[part 5 of 6: packages /DBC_SysDesc_C_CANFD/Pkg_Cluster to /DBC_SysDesc_C_CANFD/Pkg_Signal]
AUTOSAR XML (schema 4-2-2)
package /DBC_SysDesc_C_CANFD/Pkg_Cluster
  can cluster C_CANFD: baudrate=500000, protocol-name=CAN, can-fd-baudrate=200000
    can physical channel C_CANFD_Channel: comm-connectors=[Conn_C_CANFD_MVCU]
      frame IBC_0x186: id 0x186, to MVCU, frame-length=32, can-addressing-mode=STANDARD, can-fd-frame-support=true, can-frame-rx-behavior=CAN-FD
        carries pdu IBC_0x186: packing-byte-order=little-endian, start-position=0, update-indication-bit-position=-1
        pdu IBC_0x186: length=32, transmission-mode-false-timing=cyclic-timing={time-offset=0.0, time-period=0.01}, transmission-mode-true-timing=cyclic-timing={time-offset=0.0, time-period=0.01}
          transmission-mode-conditions:
            {data-filter={data-filter-type=ALWAYS, max=255, min=0, offset=0}, i-signal-in-i-pdu=IBC_CRC_186}
            {data-filter={data-filter-type=ALWAYS, max=15, min=0, offset=0}, i-signal-in-i-pdu=IBC_RollingCounter_186}
            {data-filter={data-filter-type=ALWAYS, max=1, min=0, offset=0}, i-signal-in-i-pdu=IBC_WheelPressureReliabilityFL}
            {data-filter={data-filter-type=ALWAYS, max=1, min=0, offset=0}, i-signal-in-i-pdu=IBC_WheelPressureReliabilityFR}
            {data-filter={data-filter-type=ALWAYS, max=1, min=0, offset=0}, i-signal-in-i-pdu=IBC_WheelPressureReliabilityRL}
            {data-filter={data-filter-type=ALWAYS, max=1, min=0, offset=0}, i-signal-in-i-pdu=IBC_WheelPressureReliabilityRR}
            {data-filter={data-filter-type=ALWAYS, max=256, min=0, offset=0}, i-signal-in-i-pdu=IBC_WheelCylinderPressure_FL}
            {data-filter={data-filter-type=ALWAYS, max=256, min=0, offset=0}, i-signal-in-i-pdu=IBC_WheelCylinderPressure_FR}
            {data-filter={data-filter-type=ALWAYS, max=256, min=0, offset=0}, i-signal-in-i-pdu=IBC_WheelCylinderPressure_RL}
            {data-filter={data-filter-type=ALWAYS, max=256, min=0, offset=0}, i-signal-in-i-pdu=IBC_WheelCylinderPressure_RR}
            {data-filter={data-filter-type=ALWAYS, max=1, min=0, offset=0}, i-signal-in-i-pdu=IBC_WheelSlipFLVD}
            {data-filter={data-filter-type=ALWAYS, max=1, min=0, offset=0}, i-signal-in-i-pdu=IBC_WheelSlipFRVD}
            {data-filter={data-filter-type=ALWAYS, max=1, min=0, offset=0}, i-signal-in-i-pdu=IBC_WheelSlipRLVD}
            {data-filter={data-filter-type=ALWAYS, max=1, min=0, offset=0}, i-signal-in-i-pdu=IBC_WheelSlipRRVD}
            {data-filter={data-filter-type=ALWAYS, max=254, min=0}, i-signal-in-i-pdu=IBC_WheelSlipFL}
            {data-filter={data-filter-type=ALWAYS, max=254, min=0}, i-signal-in-i-pdu=IBC_WheelSlipFR}
            {data-filter={data-filter-type=ALWAYS, max=254, min=0}, i-signal-in-i-pdu=IBC_WheelSlipRL}
            {data-filter={data-filter-type=ALWAYS, max=254, min=0}, i-signal-in-i-pdu=IBC_WheelSlipRR}
            {data-filter={data-filter-type=ALWAYS, max=100, min=0, offset=0}, i-signal-in-i-pdu=IBC_Slop_Pencent}
          signal IBC_CRC_186: start 0, 8 bit, little-endian, init-value=0, base-type=uint8, implementation-data-type=DT_IBC_CRC_186, update-indication-bit-position=-1, to MVCU
          signal IBC_RollingCounter_186: start 8, 4 bit, little-endian, init-value=0, base-type=uint8, implementation-data-type=DT_IBC_RollingCounter_186, update-indication-bit-position=-1, to MVCU
          signal IBC_WheelPressureReliabilityFL: start 68, 1 bit, little-endian, init-value=0, base-type=uint8, implementation-data-type=DT_IBC_WheelPressureReliabilityFL, update-indication-bit-position=-1, to MVCU
          signal IBC_WheelPressureReliabilityFR: start 69, 1 bit, little-endian, init-value=0, base-type=uint8, implementation-data-type=DT_IBC_WheelPressureReliabilityFR, update-indication-bit-position=-1, to MVCU
          signal IBC_WheelPressureReliabilityRL: start 70, 1 bit, little-endian, init-value=0, base-type=uint8, implementation-data-type=DT_IBC_WheelPressureReliabilityRL, update-indication-bit-position=-1, to MVCU
          signal IBC_WheelPressureReliabilityRR: start 71, 1 bit, little-endian, init-value=0, base-type=uint8, implementation-data-type=DT_IBC_WheelPressureReliabilityRR, update-indication-bit-position=-1, to MVCU
          signal IBC_WheelCylinderPressure_FL: start 192, 11 bit, little-endian, init-value=0, base-type=uint8, implementation-data-type=DT_IBC_WheelCylinderPressure_FL, update-indication-bit-position=-1, to MVCU
          signal IBC_WheelCylinderPressure_FR: start 208, 11 bit, little-endian, init-value=0, base-type=uint8, implementation-data-type=DT_IBC_WheelCylinderPressure_FR, update-indication-bit-position=-1, to MVCU
          signal IBC_WheelCylinderPressure_RL: start 224, 11 bit, little-endian, init-value=0, base-type=uint8, implementation-data-type=DT_IBC_WheelCylinderPressure_RL, update-indication-bit-position=-1, to MVCU
          signal IBC_WheelCylinderPressure_RR: start 240, 11 bit, little-endian, init-value=0, base-type=uint8, implementation-data-type=DT_IBC_WheelCylinderPressure_RR, update-indication-bit-position=-1, to MVCU
          signal IBC_WheelSlipFLVD: start 76, 1 bit, little-endian, init-value=0, base-type=uint8, implementation-data-type=DT_IBC_WheelSlipFLVD, update-indication-bit-position=-1, to MVCU
          signal IBC_WheelSlipFRVD: start 77, 1 bit, little-endian, init-value=0, base-type=uint8, implementation-data-type=DT_IBC_WheelSlipFRVD, update-indication-bit-position=-1, to MVCU
          signal IBC_WheelSlipRLVD: start 78, 1 bit, little-endian, init-value=0, base-type=uint8, implementation-data-type=DT_IBC_WheelSlipRLVD, update-indication-bit-position=-1, to MVCU
          signal IBC_WheelSlipRRVD: start 79, 1 bit, little-endian, init-value=0, base-type=uint8, implementation-data-type=DT_IBC_WheelSlipRRVD, update-indication-bit-position=-1, to MVCU
          signal IBC_WheelSlipFL: start 80, 8 bit, little-endian, init-value=0, base-type=uint8, implementation-data-type=DT_IBC_WheelSlipFL, update-indication-bit-position=-1, to MVCU
          signal IBC_WheelSlipFR: start 88, 8 bit, little-endian, init-value=0, base-type=uint8, implementation-data-type=DT_IBC_WheelSlipFR, update-indication-bit-position=-1, to MVCU
          signal IBC_WheelSlipRL: start 96, 8 bit, little-endian, init-value=0, base-type=uint8, implementation-data-type=DT_IBC_WheelSlipRL, update-indication-bit-position=-1, to MVCU
          signal IBC_WheelSlipRR: start 104, 8 bit, little-endian, init-value=0, base-type=uint8, implementation-data-type=DT_IBC_WheelSlipRR, update-indication-bit-position=-1, to MVCU
          signal IBC_Slop_Pencent: start 136, 8 bit, little-endian, init-value=0, base-type=uint8, implementation-data-type=DT_IBC_Slop_Pencent, update-indication-bit-position=-1, to MVCU
      frame LMC_0xFA: id 0xFA, to MVCU, frame-length=16, can-addressing-mode=STANDARD, can-fd-frame-support=true, can-frame-rx-behavior=CAN-FD
        carries pdu LMC_0xFA: packing-byte-order=little-endian, start-position=0, update-indication-bit-position=-1
        pdu LMC_0xFA: length=32, transmission-mode-false-timing=cyclic-timing={time-offset=0.0, time-period=0.01}, transmission-mode-true-timing=cyclic-timing={time-offset=0.0, time-period=0.01}
          transmission-mode-conditions:
            {data-filter={data-filter-type=ALWAYS, max=255, min=0, offset=0}, i-signal-in-i-pdu=LMC_CRC_FA}
            {data-filter={data-filter-type=ALWAYS, max=15, min=0, offset=0}, i-signal-in-i-pdu=LMC_RollingCounter_FA}
            {data-filter={data-filter-type=NEW-IS-WITHIN, max=800, min=0}, i-signal-in-i-pdu=LMC_EngTorqDec_Main}
            {data-filter={data-filter-type=ALWAYS, max=1, min=0, offset=0}, i-signal-in-i-pdu=LMC_EngTorqDecActive_Main}
            {data-filter={data-filter-type=ALWAYS, max=3, min=0, offset=0}, i-signal-in-i-pdu=LMC_AMM_St}
            {data-filter={data-filter-type=NEW-IS-WITHIN, max=800, min=0}, i-signal-in-i-pdu=LMC_EngTorqInc_Main}
            {data-filter={data-filter-type=ALWAYS, max=1, min=0, offset=0}, i-signal-in-i-pdu=LMC_EngTorqIncActive_Main}
            {data-filter={data-filter-type=NEW-IS-WITHIN, max=800, min=0}, i-signal-in-i-pdu=LMC_EngTorqDec_Sub}
            {data-filter={data-filter-type=ALWAYS, max=1, min=0, offset=0}, i-signal-in-i-pdu=LMC_EngTorqDecActive_Sub}
            {data-filter={data-filter-type=NEW-IS-WITHIN, max=800, min=0}, i-signal-in-i-pdu=LMC_EngTorqInc_Sub}
            {data-filter={data-filter-type=ALWAYS, max=1, min=0, offset=0}, i-signal-in-i-pdu=LMC_EngTorqIncActive_Sub}
            {data-filter={data-filter-type=ALWAYS, max=1, min=0, offset=0}, i-signal-in-i-pdu=LMC_HSPC_ActiveSt}
            {data-filter={data-filter-type=ALWAYS, max=1, min=0, offset=0}, i-signal-in-i-pdu=LMC_FTSC_ActiveSt}
            {data-filter={data-filter-type=ALWAYS, max=1, min=0, offset=0}, i-signal-in-i-pdu=LMC_SDRM_ActiveSt}
            {data-filter={data-filter-type=ALWAYS, max=1, min=0, offset=0}, i-signal-in-i-pdu=LMC_NSPC_ActiveSt}
            {data-filter={data-filter-type=ALWAYS, max=1, min=0, offset=0}, i-signal-in-i-pdu=LMC_EAF_ActiveSt}
            {data-filter={data-filter-type=ALWAYS, max=1, min=0, offset=0}, i-signal-in-i-pdu=LMC_SelfCheckSt}
            {data-filter={data-filter-type=ALWAYS, max=3, min=0, offset=0}, i-signal-in-i-pdu=LMC_WBDC_ActiveSt}
            {data-filter={data-filter-type=ALWAYS, max=3, min=0, offset=0}, i-signal-in-i-pdu=LMC_LSFCActiveSt}
            {data-filter={data-filter-type=ALWAYS, max=800, min=0, offset=0}, i-signal-in-i-pdu=LMC_EngTorqDec_Main_R}
            {data-filter={data-filter-type=ALWAYS, max=1, min=0, offset=0}, i-signal-in-i-pdu=LMC_EngTorqDecActive_Main_R}
            {data-filter={data-filter-type=ALWAYS, max=800, min=0, offset=0}, i-signal-in-i-pdu=LMC_EngTorqInc_Main_R}
            {data-filter={data-filter-type=ALWAYS, max=1, min=0, offset=0}, i-signal-in-i-pdu=LMC_EngTorqIncActive_Main_R}
          signal LMC_CRC_FA: start 0, 8 bit, little-endian, init-value=0, base-type=uint8, implementation-data-type=DT_LMC_CRC_FA, update-indication-bit-position=-1, to MVCU
          signal LMC_RollingCounter_FA: start 8, 4 bit, little-endian, init-value=0, base-type=uint8, implementation-data-type=DT_LMC_RollingCounter_FA, update-indication-bit-position=-1, to MVCU
          signal LMC_EngTorqDec_Main: start 16, 10 bit, little-endian, init-value=0, base-type=uint16, implementation-data-type=DT_LMC_EngTorqDec_Main, update-indication-bit-position=-1, to MVCU
          signal LMC_EngTorqDecActive_Main: start 26, 1 bit, little-endian, init-value=0, base-type=uint8, implementation-data-type=DT_LMC_EngTorqDecActive_Main, update-indication-bit-position=-1, to MVCU
          signal LMC_AMM_St: start 27, 2 bit, little-endian, init-value=0, base-type=uint8, implementation-data-type=DT_LMC_AMM_St, update-indication-bit-position=-1, to MVCU
          signal LMC_EngTorqInc_Main: start 32, 10 bit, little-endian, init-value=0, base-type=uint16, implementation-data-type=DT_LMC_EngTorqInc_Main, update-indication-bit-position=-1, to MVCU
          signal LMC_EngTorqIncActive_Main: start 42, 1 bit, little-endian, init-value=0, base-type=uint8, implementation-data-type=DT_LMC_EngTorqIncActive_Main, update-indication-bit-position=-1, to MVCU
          signal LMC_EngTorqDec_Sub: start 48, 10 bit, little-endian, init-value=0, base-type=uint16, implementation-data-type=DT_LMC_EngTorqDec_Sub, update-indication-bit-position=-1, to MVCU
          signal LMC_EngTorqDecActive_Sub: start 58, 1 bit, little-endian, init-value=0, base-type=uint8, implementation-data-type=DT_LMC_EngTorqDecActive_Sub, update-indication-bit-position=-1, to MVCU
          signal LMC_EngTorqInc_Sub: start 64, 10 bit, little-endian, init-value=0, base-type=uint16, implementation-data-type=DT_LMC_EngTorqInc_Sub, update-indication-bit-position=-1, to MVCU
          signal LMC_EngTorqIncActive_Sub: start 74, 1 bit, little-endian, init-value=0, base-type=uint8, implementation-data-type=DT_LMC_EngTorqIncActive_Sub, update-indication-bit-position=-1, to MVCU
          signal LMC_SysSt: start 176, 2 bit, little-endian, init-value=0, base-type=uint8, implementation-data-type=DT_LMC_SysSt, update-indication-bit-position=-1, to MVCU
          signal LMC_HSPC_ActiveSt: start 180, 1 bit, little-endian, init-value=0, base-type=uint8, implementation-data-type=DT_LMC_HSPC_ActiveSt, update-indication-bit-position=-1, to MVCU
          signal LMC_FTSC_ActiveSt: start 181, 1 bit, little-endian, init-value=0, base-type=uint8, implementation-data-type=DT_LMC_FTSC_ActiveSt, update-indication-bit-position=-1, to MVCU
          signal LMC_SDRM_ActiveSt: start 182, 1 bit, little-endian, init-value=0, base-type=uint8, implementation-data-type=DT_LMC_SDRM_ActiveSt, update-indication-bit-position=-1, to MVCU
          signal LMC_NSPC_ActiveSt: start 183, 1 bit, little-endian, init-value=0, base-type=uint8, implementation-data-type=DT_LMC_NSPC_ActiveSt, update-indication-bit-position=-1, to MVCU
          signal LMC_EAF_ActiveSt: start 184, 1 bit, little-endian, init-value=0, base-type=uint8, implementation-data-type=DT_LMC_EAF_ActiveSt, update-indication-bit-position=-1, to MVCU
          signal LMC_SelfCheckSt: start 185, 1 bit, little-endian, init-value=0, base-type=uint8, implementation-data-type=DT_LMC_SelfCheckSt, update-indication-bit-position=-1, to MVCU
          signal LMC_WBDC_ActiveSt: start 186, 2 bit, little-endian, init-value=0, base-type=uint8, implementation-data-type=DT_LMC_WBDC_ActiveSt, update-indication-bit-position=-1, to MVCU
          signal LMC_LSFCActiveSt: start 230, 2 bit, little-endian, init-value=0, base-type=uint8, implementation-data-type=DT_LMC_LSFCActiveSt, update-indication-bit-position=-1, to MVCU
          signal LMC_EngTorqDec_Main_R: start 232, 10 bit, little-endian, init-value=0, base-type=uint16, update-indication-bit-position=-1, to MVCU
          signal LMC_EngTorqDecActive_Main_R: start 242, 1 bit, little-endian, init-value=0, base-type=uint8, update-indication-bit-position=-1, to MVCU
          signal LMC_EngTorqInc_Main_R: start 244, 10 bit, little-endian, init-value=0, base-type=uint16, update-indication-bit-position=-1, to MVCU
          signal LMC_EngTorqIncActive_Main_R: start 254, 1 bit, little-endian, init-value=0, base-type=uint8, update-indication-bit-position=-1, to MVCU
      frame LMC_0x18C: id 0x18C, to MVCU, frame-length=32, can-addressing-mode=STANDARD, can-fd-frame-support=true, can-frame-rx-behavior=CAN-FD
        carries pdu LMC_0x18C: packing-byte-order=little-endian, start-position=0, update-indication-bit-position=-1
        pdu LMC_0x18C: length=32, transmission-mode-false-timing=cyclic-timing={time-offset=0.0, time-period=0.02}, transmission-mode-true-timing=cyclic-timing={time-offset=0.0, time-period=0.02}
          transmission-mode-conditions:
            {data-filter={data-filter-type=ALWAYS, max=255, min=0, offset=0}, i-signal-in-i-pdu=LMC_CRC_18C}
            {data-filter={data-filter-type=ALWAYS, max=15, min=0, offset=0}, i-signal-in-i-pdu=LMC_RollingCounter_18C}
            {data-filter={data-filter-type=ALWAYS, max=32767, min=0, offset=0}, i-signal-in-i-pdu=LMC_TqTotalBrakeTorque}
            {data-filter={data-filter-type=ALWAYS, max=1, min=0, offset=0}, i-signal-in-i-pdu=LMC_TqTotalBrakeTorque_Valid}
            {data-filter={data-filter-type=ALWAYS, max=7, min=0, offset=0}, i-signal-in-i-pdu=LMC_CmpUTurnLockwhists}
          signal LMC_CRC_18C: start 0, 8 bit, little-endian, init-value=0, base-type=uint8, implementation-data-type=DT_LMC_CRC_18C, update-indication-bit-position=-1, to MVCU
          signal LMC_RollingCounter_18C: start 8, 4 bit, little-endian, init-value=0, base-type=uint8, implementation-data-type=DT_LMC_RollingCounter_18C, update-indication-bit-position=-1, to MVCU
          signal LMC_TqTotalBrakeTorque: start 80, 15 bit, little-endian, init-value=0, base-type=uint16, implementation-data-type=DT_LMC_TqTotalBrakeTorque, update-indication-bit-position=-1, to MVCU
          signal LMC_TqTotalBrakeTorque_Valid: start 95, 1 bit, little-endian, init-value=0, base-type=uint8, implementation-data-type=DT_LMC_TqTotalBrakeTorque_Valid, update-indication-bit-position=-1, to MVCU
          signal LMC_CmpUTurnLockwhists: start 132, 3 bit, little-endian, init-value=0, base-type=uint8, implementation-data-type=DT_LMC_CmpUTurnLockwhists, update-indication-bit-position=-1, to MVCU
      frame ADDC_0x83: id 0x83, to MVCU, frame-length=32, can-addressing-mode=STANDARD, can-fd-frame-support=true, can-frame-rx-behavior=CAN-FD
        carries pdu ADDC_0x83: packing-byte-order=little-endian, start-position=0, update-indication-bit-position=-1
        pdu ADDC_0x83: length=32, transmission-mode-false-timing=cyclic-timing={time-offset=0.0, time-period=0.02}, transmission-mode-true-timing=cyclic-timing={time-offset=0.0, time-period=0.02}
          transmission-mode-conditions:
            {data-filter={data-filter-type=ALWAYS, max=255, min=0, offset=0}, i-signal-in-i-pdu=ADDC_CRC_83}
            {data-filter={data-filter-type=ALWAYS, max=1, min=0, offset=0}, i-signal-in-i-pdu=ADDC_ACC_AVHReq}
            {data-filter={data-filter-type=ALWAYS, max=1, min=0, offset=0}, i-signal-in-i-pdu=ADDC_ACC_HoldSts}
            {data-filter={data-filter-type=ALWAYS, max=16383, min=0, offset=0}, i-signal-in-i-pdu=ADDC_ACCTargetTrq}
            {data-filter={data-filter-type=ALWAYS, max=1, min=0, offset=0}, i-signal-in-i-pdu=ADDC_ACCTargetTrqVD}
            {data-filter={data-filter-type=ALWAYS, max=1, min=0, offset=0}, i-signal-in-i-pdu=ADDC_ACCTargetTrqBrkVD}
            {data-filter={data-filter-type=ALWAYS, max=8191, min=0, offset=0}, i-signal-in-i-pdu=ADDC_ACCTargetTrqBrk}
            {data-filter={data-filter-type=ALWAYS, max=7, min=0, offset=0}, i-signal-in-i-pdu=ADDC_MAIWarnTrqCtrlFlg}
            {data-filter={data-filter-type=ALWAYS, max=15, min=0, offset=0}, i-signal-in-i-pdu=ADDC_RollingCounter_83}
            {data-filter={data-filter-type=ALWAYS, max=3, min=0, offset=0}, i-signal-in-i-pdu=ADDC_ACC_FunType}
            {data-filter={data-filter-type=ALWAYS, max=7, min=0, offset=0}, i-signal-in-i-pdu=ADDC_ACCMode}
            {data-filter={data-filter-type=ALWAYS, max=1, min=0, offset=0}, i-signal-in-i-pdu=ADDC_Driveoff_Request}
            {data-filter={data-filter-type=ALWAYS, max=1, min=0, offset=0}, i-signal-in-i-pdu=ADDC_DecToStop}
            {data-filter={data-filter-type=ALWAYS, max=1, min=0, offset=0}, i-signal-in-i-pdu=ADDC_ACCAvailable}
            {data-filter={data-filter-type=ALWAYS, max=255, min=0}, i-signal-in-i-pdu=ADDC_ACCTargetAcc}
            {data-filter={data-filter-type=ALWAYS, max=1, min=0, offset=0}, i-signal-in-i-pdu=ADDC_ACCTargetAccVD}
            {data-filter={data-filter-type=ALWAYS, max=3, min=0, offset=0}, i-signal-in-i-pdu=ADDC_ACC_RecordingPulse}
            {data-filter={data-filter-type=ALWAYS, max=1, min=0, offset=0}, i-signal-in-i-pdu=ADDC_VehicleSpeedCtlVD}
            {data-filter={data-filter-type=NEW-IS-WITHIN, max=1800, min=0, offset=0}, i-signal-in-i-pdu=ADDC_VehicleSpeedCtl}
            {data-filter={data-filter-type=ALWAYS, max=3, min=0, offset=0}, i-signal-in-i-pdu=ADDC_ACC_EPBReq}
            {data-filter={data-filter-type=ALWAYS, max=3, min=0, offset=0}, i-signal-in-i-pdu=ADDC_ACC_VehicleDirectCtl}
            {data-filter={data-filter-type=ALWAYS, max=1, min=0, offset=0}, i-signal-in-i-pdu=ADDC_ACC_VehicleDirectCtlVD}
            {data-filter={data-filter-type=NEW-IS-WITHIN, max=64000, min=0}, i-signal-in-i-pdu=ADDC_AEBTargetDec}
            {data-filter={data-filter-type=ALWAYS, max=1, min=0, offset=0}, i-signal-in-i-pdu=ADDC_AEBDecCtrl}
            {data-filter={data-filter-type=ALWAYS, max=7, min=0, offset=0}, i-signal-in-i-pdu=ADDC_AEBMode}
            {data-filter={data-filter-type=ALWAYS, max=1, min=0, offset=0}, i-signal-in-i-pdu=ADDC_AEBAvailable}
            {data-filter={data-filter-type=ALWAYS, max=1, min=0, offset=0}, i-signal-in-i-pdu=ADDC_ACC_VLCCtlReq}
            {data-filter={data-filter-type=ALWAYS, max=1, min=0, offset=0}, i-signal-in-i-pdu=ADDC_ACC_OvrdSts}
            {data-filter={data-filter-type=ALWAYS, max=1, min=0, offset=0}, i-signal-in-i-pdu=ADDC_RCTB_DecReq}
            {data-filter={data-filter-type=ALWAYS, max=1, min=0, offset=0}, i-signal-in-i-pdu=ADDC_RAEB_DecReq}
            {data-filter={data-filter-type=ALWAYS, max=1, min=0, offset=0}, i-signal-in-i-pdu=ADDC_MEB_DecReq}
          signal ADDC_CRC_83: start 0, 8 bit, little-endian, init-value=0, base-type=uint8, implementation-data-type=DT_ADDC_CRC_83, update-indication-bit-position=-1, to MVCU
          signal ADDC_ACC_AVHReq: start 62, 1 bit, little-endian, init-value=0, base-type=uint8, implementation-data-type=DT_ADDC_ACC_AVHReq, update-indication-bit-position=-1, to MVCU
          signal ADDC_ACC_HoldSts: start 61, 1 bit, little-endian, init-value=0, base-type=uint8, implementation-data-type=DT_ADDC_ACC_HoldSts, update-indication-bit-position=-1, to MVCU
          signal ADDC_ACCTargetTrq: start 242, 14 bit, little-endian, init-value=0, base-type=uint16, implementation-data-type=DT_ADDC_ACCTargetTrq, update-indication-bit-position=-1, to MVCU
          signal ADDC_ACCTargetTrqVD: start 241, 1 bit, little-endian, init-value=0, base-type=uint8, implementation-data-type=DT_ADDC_ACCTargetTrqVD, update-indication-bit-position=-1, to MVCU
          signal ADDC_ACCTargetTrqBrkVD: start 240, 1 bit, little-endian, init-value=0, base-type=uint8, implementation-data-type=DT_ADDC_ACCTargetTrqBrkVD, update-indication-bit-position=-1, to MVCU
          signal ADDC_ACCTargetTrqBrk: start 227, 13 bit, little-endian, init-value=0, base-type=uint16, implementation-data-type=DT_ADDC_ACCTargetTrqBrk, update-indication-bit-position=-1, to MVCU
          signal ADDC_MAIWarnTrqCtrlFlg: start 224, 3 bit, little-endian, init-value=0, base-type=uint8, implementation-data-type=DT_ADDC_MAIWarnTrqCtrlFlg, update-indication-bit-position=-1, to MVCU
          signal ADDC_RollingCounter_83: start 8, 4 bit, little-endian, init-value=0, base-type=uint8, implementation-data-type=DT_ADDC_RollingCounter_83, update-indication-bit-position=-1, to MVCU
          signal ADDC_ACC_FunType: start 20, 2 bit, little-endian, init-value=0, base-type=uint8, implementation-data-type=DT_ADDC_ACC_FunType, update-indication-bit-position=-1, to MVCU
          signal ADDC_ACCMode: start 25, 3 bit, little-endian, init-value=0, base-type=uint8, implementation-data-type=DT_ADDC_ACCMode, update-indication-bit-position=-1, to MVCU
          signal ADDC_Driveoff_Request: start 28, 1 bit, little-endian, init-value=0, base-type=uint8, implementation-data-type=DT_ADDC_Driveoff_Request, update-indication-bit-position=-1, to MVCU
          signal ADDC_DecToStop: start 29, 1 bit, little-endian, init-value=0, base-type=uint8, implementation-data-type=DT_ADDC_DecToStop, update-indication-bit-position=-1, to MVCU
          signal ADDC_ACCAvailable: start 30, 1 bit, little-endian, init-value=0, base-type=uint8, implementation-data-type=DT_ADDC_ACCAvailable, update-indication-bit-position=-1, to MVCU
          signal ADDC_ACCTargetAcc: start 32, 8 bit, little-endian, init-value=0, base-type=uint8, implementation-data-type=DT_ADDC_ACCTargetAcc, update-indication-bit-position=-1, to MVCU
          signal ADDC_ACCTargetAccVD: start 40, 1 bit, little-endian, init-value=0, base-type=uint8, implementation-data-type=DT_ADDC_ACCTargetAccVD, update-indication-bit-position=-1, to MVCU
          signal ADDC_ACC_RecordingPulse: start 42, 2 bit, little-endian, init-value=0, base-type=uint8, implementation-data-type=DT_ADDC_ACC_RecordingPulse, update-indication-bit-position=-1, to MVCU
          signal ADDC_VehicleSpeedCtlVD: start 44, 1 bit, little-endian, init-value=0, base-type=uint8, implementation-data-type=DT_ADDC_VehicleSpeedCtlVD, update-indication-bit-position=-1, to MVCU
          signal ADDC_VehicleSpeedCtl: start 45, 11 bit, little-endian, init-value=0, base-type=uint16, implementation-data-type=DT_ADDC_VehicleSpeedCtl, update-indication-bit-position=-1, to MVCU
          signal ADDC_ACC_EPBReq: start 56, 2 bit, little-endian, init-value=0, base-type=uint8, implementation-data-type=DT_ADDC_ACC_EPBReq, update-indication-bit-position=-1, to MVCU
          signal ADDC_ACC_VehicleDirectCtl: start 58, 2 bit, little-endian, init-value=0, base-type=uint8, implementation-data-type=DT_ADDC_ACC_VehicleDirectCtl, update-indication-bit-position=-1, to MVCU
          signal ADDC_ACC_VehicleDirectCtlVD: start 60, 1 bit, little-endian, init-value=0, base-type=uint8, implementation-data-type=DT_ADDC_ACC_VehicleDirectCtlVD, update-indication-bit-position=-1, to MVCU
          signal ADDC_AEBTargetDec: start 64, 16 bit, little-endian, init-value=0, base-type=uint16, implementation-data-type=DT_ADDC_AEBTargetDec, update-indication-bit-position=-1, to MVCU
          signal ADDC_AEBDecCtrl: start 80, 1 bit, little-endian, init-value=0, base-type=uint8, implementation-data-type=DT_ADDC_AEBDecCtrl, update-indication-bit-position=-1, to MVCU
          signal ADDC_AEBMode: start 91, 3 bit, little-endian, init-value=0, base-type=uint8, implementation-data-type=DT_ADDC_AEBMode, update-indication-bit-position=-1, to MVCU
          signal ADDC_AEBAvailable: start 94, 1 bit, little-endian, init-value=0, base-type=uint8, implementation-data-type=DT_ADDC_AEBAvailable, update-indication-bit-position=-1, to MVCU
          signal ADDC_ACC_VLCCtlReq: start 178, 1 bit, little-endian, init-value=0, base-type=uint8, implementation-data-type=DT_ADDC_ACC_VLCCtlReq, update-indication-bit-position=-1, to MVCU
          signal ADDC_ACC_OvrdSts: start 179, 1 bit, little-endian, init-value=0, base-type=uint8, implementation-data-type=DT_ADDC_ACC_OvrdSts, update-indication-bit-position=-1, to MVCU
          signal ADDC_RCTB_DecReq: start 181, 1 bit, little-endian, init-value=0, base-type=uint8, implementation-data-type=DT_ADDC_RCTB_DecReq, update-indication-bit-position=-1, to MVCU
          signal ADDC_RAEB_DecReq: start 193, 1 bit, little-endian, init-value=0, base-type=uint8, implementation-data-type=DT_ADDC_RAEB_DecReq, update-indication-bit-position=-1, to MVCU
          signal ADDC_MEB_DecReq: start 195, 1 bit, little-endian, init-value=0, base-type=uint8, implementation-data-type=DT_ADDC_MEB_DecReq, update-indication-bit-position=-1, to MVCU
      frame ADDC_0x84: id 0x84, to MVCU, frame-length=16, can-addressing-mode=STANDARD, can-fd-frame-support=true, can-frame-rx-behavior=CAN-FD
        carries pdu ADDC_0x84: packing-byte-order=little-endian, start-position=0, update-indication-bit-position=-1
        pdu ADDC_0x84: length=16, transmission-mode-false-timing=cyclic-timing={time-offset=0.0, time-period=0.02}, transmission-mode-true-timing=cyclic-timing={time-offset=0.0, time-period=0.02}
          transmission-mode-conditions:
            {data-filter={data-filter-type=ALWAYS, max=255, min=0, offset=0}, i-signal-in-i-pdu=ADDC_CRC_84}
            {data-filter={data-filter-type=ALWAYS, max=1, min=0, offset=0}, i-signal-in-i-pdu=ADDC_APS_AVHReq}
            {data-filter={data-filter-type=ALWAYS, max=1, min=0, offset=0}, i-signal-in-i-pdu=ADDC_APS_HoldSts}
            {data-filter={data-filter-type=ALWAYS, max=1, min=0, offset=0}, i-signal-in-i-pdu=ADDC_APSTargetTrqBrkVD}
            {data-filter={data-filter-type=ALWAYS, max=8191, min=0, offset=0}, i-signal-in-i-pdu=ADDC_APSTargetTrqBrk}
            {data-filter={data-filter-type=ALWAYS, max=1, min=0, offset=0}, i-signal-in-i-pdu=ADDC_APSTargetTrqVD}
            {data-filter={data-filter-type=ALWAYS, max=16383, min=0, offset=0}, i-signal-in-i-pdu=ADDC_APSTargetTrq}
            {data-filter={data-filter-type=ALWAYS, max=1, min=0, offset=0}, i-signal-in-i-pdu=ADDC_safety_valid}
            {data-filter={data-filter-type=ALWAYS, max=7, min=0, offset=0}, i-signal-in-i-pdu=ADDC_rearsafety_level}
            {data-filter={data-filter-type=ALWAYS, max=7, min=0, offset=0}, i-signal-in-i-pdu=ADDC_frontsafety_level}
            {data-filter={data-filter-type=ALWAYS, max=7, min=0, offset=0}, i-signal-in-i-pdu=ADDC_rightsafety_level}
            {data-filter={data-filter-type=ALWAYS, max=7, min=0, offset=0}, i-signal-in-i-pdu=ADDC_leftsafety_level}
            {data-filter={data-filter-type=ALWAYS, max=15, min=0, offset=0}, i-signal-in-i-pdu=ADDC_RollingCounter_84}
            {data-filter={data-filter-type=ALWAYS, max=1, min=0, offset=0}, i-signal-in-i-pdu=ADDC_APS_EnableReq}
            {data-filter={data-filter-type=ALWAYS, max=1, min=0, offset=0}, i-signal-in-i-pdu=ADDC_APS_WorkSts}
            {data-filter={data-filter-type=ALWAYS, max=1, min=0, offset=0}, i-signal-in-i-pdu=ADDC_APS_PDCVehicleDirectCtlVD}
            {data-filter={data-filter-type=ALWAYS, max=1, min=0, offset=0}, i-signal-in-i-pdu=ADDC_APS_VehicleSpeedCtlVD}
            {data-filter={data-filter-type=ALWAYS, max=3, min=0, offset=0}, i-signal-in-i-pdu=ADDC_APS_PDC_VehicleDirectCtl}
            {data-filter={data-filter-type=NEW-IS-WITHIN, max=65000, min=0}, i-signal-in-i-pdu=ADDC_APS_PDC_SWAngCtl}
            {data-filter={data-filter-type=ALWAYS, max=3, min=0, offset=0}, i-signal-in-i-pdu=ADDC_APS_ParkingReq}
            {data-filter={data-filter-type=ALWAYS, max=1, min=0, offset=0}, i-signal-in-i-pdu=ADDC_APS_EmergenceBrake}
            {data-filter={data-filter-type=ALWAYS, max=1, min=0, offset=0}, i-signal-in-i-pdu=ADDC_APS_TargetAccVD}
            {data-filter={data-filter-type=ALWAYS, max=240, min=0}, i-signal-in-i-pdu=ADDC_APS_TargetAcc}
            {data-filter={data-filter-type=ALWAYS, max=63, min=0, offset=0}, i-signal-in-i-pdu=ADDC_APS_VehicleSpeedCtl}
            {data-filter={data-filter-type=ALWAYS, max=1, min=0, offset=0}, i-signal-in-i-pdu=ADDC_APS_DecToStop}
            {data-filter={data-filter-type=ALWAYS, max=1, min=0, offset=0}, i-signal-in-i-pdu=ADDC_APS_Driveoff_Request}
            {data-filter={data-filter-type=ALWAYS, max=7, min=0, offset=0}, i-signal-in-i-pdu=ADDC_APS_FuncType}
            {data-filter={data-filter-type=ALWAYS, max=1, min=0, offset=0}, i-signal-in-i-pdu=ADDC_APS_Available}
          signal ADDC_CRC_84: start 0, 8 bit, little-endian, init-value=0, base-type=uint8, implementation-data-type=DT_ADDC_CRC_84, update-indication-bit-position=-1, to MVCU
          signal ADDC_APS_AVHReq: start 45, 1 bit, little-endian, init-value=0, base-type=uint8, implementation-data-type=DT_ADDC_APS_AVHReq, update-indication-bit-position=-1, to MVCU
          signal ADDC_APS_HoldSts: start 44, 1 bit, little-endian, init-value=0, base-type=uint8, implementation-data-type=DT_ADDC_APS_HoldSts, update-indication-bit-position=-1, to MVCU
          signal ADDC_APSTargetTrqBrkVD: start 125, 1 bit, little-endian, init-value=0, base-type=uint8, implementation-data-type=DT_ADDC_APSTargetTrqBrkVD, update-indication-bit-position=-1, to MVCU
          signal ADDC_APSTargetTrqBrk: start 112, 13 bit, little-endian, init-value=0, base-type=uint16, implementation-data-type=DT_ADDC_APSTargetTrqBrk, update-indication-bit-position=-1, to MVCU
          signal ADDC_APSTargetTrqVD: start 111, 1 bit, little-endian, init-value=0, base-type=uint8, implementation-data-type=DT_ADDC_APSTargetTrqVD, update-indication-bit-position=-1, to MVCU
          signal ADDC_APSTargetTrq: start 97, 14 bit, little-endian, init-value=0, base-type=uint16, implementation-data-type=DT_ADDC_APSTargetTrq, update-indication-bit-position=-1, to MVCU
          signal ADDC_safety_valid: start 96, 1 bit, little-endian, init-value=0, base-type=uint8, implementation-data-type=DT_ADDC_safety_valid, update-indication-bit-position=-1, to MVCU
          signal ADDC_rearsafety_level: start 93, 3 bit, little-endian, init-value=0, base-type=uint8, implementation-data-type=DT_ADDC_rearsafety_level, update-indication-bit-position=-1, to MVCU
          signal ADDC_frontsafety_level: start 90, 3 bit, little-endian, init-value=0, base-type=uint8, implementation-data-type=DT_ADDC_frontsafety_level, update-indication-bit-position=-1, to MVCU
          signal ADDC_rightsafety_level: start 87, 3 bit, little-endian, init-value=0, base-type=uint8, implementation-data-type=DT_ADDC_rightsafety_level, update-indication-bit-position=-1, to MVCU
          signal ADDC_leftsafety_level: start 84, 3 bit, little-endian, init-value=0, base-type=uint8, implementation-data-type=DT_ADDC_leftsafety_level, update-indication-bit-position=-1, to MVCU
          signal ADDC_RollingCounter_84: start 8, 4 bit, little-endian, init-value=0, base-type=uint8, implementation-data-type=DT_ADDC_RollingCounter_84, update-indication-bit-position=-1, to MVCU
          signal ADDC_APS_EnableReq: start 16, 1 bit, little-endian, init-value=0, base-type=uint8, implementation-data-type=DT_ADDC_APS_EnableReq, update-indication-bit-position=-1, to MVCU
          signal ADDC_APS_WorkSts: start 17, 1 bit, little-endian, init-value=0, base-type=uint8, implementation-data-type=DT_ADDC_APS_WorkSts, update-indication-bit-position=-1, to MVCU
          signal ADDC_APS_PDCVehicleDirectCtlVD: start 19, 1 bit, little-endian, init-value=0, base-type=uint8, implementation-data-type=DT_ADDC_APS_PDCVehicleDirectCtlVD, update-indication-bit-position=-1, to MVCU
          signal ADDC_APS_VehicleSpeedCtlVD: start 20, 1 bit, little-endian, init-value=0, base-type=uint8, implementation-data-type=DT_ADDC_APS_VehicleSpeedCtlVD, update-indication-bit-position=-1, to MVCU
          signal ADDC_APS_PDC_VehicleDirectCtl: start 21, 2 bit, little-endian, init-value=0, base-type=uint8, implementation-data-type=DT_ADDC_APS_PDC_VehicleDirectCtl, update-indication-bit-position=-1, to MVCU
          signal ADDC_APS_PDC_SWAngCtl: start 24, 16 bit, little-endian, init-value=0, base-type=uint16, implementation-data-type=DT_ADDC_APS_PDC_SWAngCtl, update-indication-bit-position=-1, to MVCU
          signal ADDC_APS_ParkingReq: start 40, 2 bit, little-endian, init-value=0, base-type=uint8, implementation-data-type=DT_ADDC_APS_ParkingReq, update-indication-bit-position=-1, to MVCU
          signal ADDC_APS_EmergenceBrake: start 42, 1 bit, little-endian, init-value=0, base-type=uint8, implementation-data-type=DT_ADDC_APS_EmergenceBrake, update-indication-bit-position=-1, to MVCU
          signal ADDC_APS_TargetAccVD: start 43, 1 bit, little-endian, init-value=0, base-type=uint8, implementation-data-type=DT_ADDC_APS_TargetAccVD, update-indication-bit-position=-1, to MVCU
          signal ADDC_APS_TargetAcc: start 56, 8 bit, little-endian, init-value=0, base-type=uint8, implementation-data-type=DT_ADDC_APS_TargetAcc, update-indication-bit-position=-1, to MVCU
          signal ADDC_APS_VehicleSpeedCtl: start 64, 6 bit, little-endian, init-value=0, base-type=uint8, implementation-data-type=DT_ADDC_APS_VehicleSpeedCtl, update-indication-bit-position=-1, to MVCU
          signal ADDC_APS_DecToStop: start 70, 1 bit, little-endian, init-value=0, base-type=uint8, implementation-data-type=DT_ADDC_APS_DecToStop, update-indication-bit-position=-1, to MVCU
          signal ADDC_APS_Driveoff_Request: start 72, 1 bit, little-endian, init-value=0, base-type=uint8, implementation-data-type=DT_ADDC_APS_Driveoff_Request, update-indication-bit-position=-1, to MVCU
          signal ADDC_APS_FuncType: start 73, 3 bit, little-endian, init-value=0, base-type=uint8, implementation-data-type=DT_ADDC_APS_FuncType, update-indication-bit-position=-1, to MVCU
          signal ADDC_APS_Available: start 76, 1 bit, little-endian, init-value=0, base-type=uint8, implementation-data-type=DT_ADDC_APS_Available, update-indication-bit-position=-1, to MVCU
      frame IBC_0xB1: id 0xB1, to MVCU, frame-length=16, can-addressing-mode=STANDARD, can-fd-frame-support=true, can-frame-rx-behavior=CAN-FD
        carries pdu IBC_0xB1: packing-byte-order=little-endian, start-position=0, update-indication-bit-position=-1
        pdu IBC_0xB1: length=16, transmission-mode-false-timing=cyclic-timing={time-offset=0.0, time-period=0.01}, transmission-mode-true-timing=cyclic-timing={time-offset=0.0, time-period=0.01}
          transmission-mode-conditions:
            {data-filter={data-filter-type=ALWAYS, max=255, min=0, offset=0}, i-signal-in-i-pdu=IBC_CRC_B1}
            {data-filter={data-filter-type=ALWAYS, max=15, min=0, offset=0}, i-signal-in-i-pdu=IBC_RollingCounter_B1}
            {data-filter={data-filter-type=NEW-IS-WITHIN, max=800, min=0}, i-signal-in-i-pdu=IBC_EngTorqDec_Main}
            {data-filter={data-filter-type=ALWAYS, max=1, min=0, offset=0}, i-signal-in-i-pdu=IBC_EngTorqDecActive_Main}
            {data-filter={data-filter-type=NEW-IS-WITHIN, max=800, min=0}, i-signal-in-i-pdu=IBC_EngTorqInc_Main}
            {data-filter={data-filter-type=ALWAYS, max=1, min=0, offset=0}, i-signal-in-i-pdu=IBC_EngTorqIncActive_Main}
            {data-filter={data-filter-type=NEW-IS-WITHIN, max=800, min=0}, i-signal-in-i-pdu=IBC_EngTorqDec_Sub}
            {data-filter={data-filter-type=ALWAYS, max=1, min=0, offset=0}, i-signal-in-i-pdu=IBC_EngTorqDecActive_Sub}
            {data-filter={data-filter-type=NEW-IS-WITHIN, max=800, min=0}, i-signal-in-i-pdu=IBC_EngTorqInc_Sub}
            {data-filter={data-filter-type=ALWAYS, max=1, min=0, offset=0}, i-signal-in-i-pdu=IBC_EngTorqIncActive_Sub}
            {data-filter={data-filter-type=ALWAYS, max=800, min=0, offset=0}, i-signal-in-i-pdu=IBC_EngTorqDec_MainR}
            {data-filter={data-filter-type=ALWAYS, max=800, min=0, offset=0}, i-signal-in-i-pdu=IBC_EngTorqDecActive_MainR}
            {data-filter={data-filter-type=ALWAYS, max=800, min=0, offset=0}, i-signal-in-i-pdu=IBC_EngTorqInc_MainR}
            {data-filter={data-filter-type=ALWAYS, max=800, min=0, offset=0}, i-signal-in-i-pdu=IBC_EngTorqIncActive_MainR}
          signal IBC_CRC_B1: start 0, 8 bit, little-endian, init-value=0, base-type=uint8, implementation-data-type=DT_IBC_CRC_B1, update-indication-bit-position=-1, to MVCU
          signal IBC_RollingCounter_B1: start 8, 4 bit, little-endian, init-value=0, base-type=uint8, implementation-data-type=DT_IBC_RollingCounter_B1, update-indication-bit-position=-1, to MVCU
          signal IBC_EngTorqDec_Main: start 16, 10 bit, little-endian, init-value=0, base-type=uint16, implementation-data-type=DT_IBC_EngTorqDec_Main, update-indication-bit-position=-1, to MVCU
          signal IBC_EngTorqDecActive_Main: start 26, 1 bit, little-endian, init-value=0, base-type=uint8, implementation-data-type=DT_IBC_EngTorqDecActive_Main, update-indication-bit-position=-1, to MVCU
          signal IBC_EngTorqInc_Main: start 32, 10 bit, little-endian, init-value=0, base-type=uint16, implementation-data-type=DT_IBC_EngTorqInc_Main, update-indication-bit-position=-1, to MVCU
          signal IBC_EngTorqIncActive_Main: start 42, 1 bit, little-endian, init-value=0, base-type=uint8, implementation-data-type=DT_IBC_EngTorqIncActive_Main, update-indication-bit-position=-1, to MVCU
          signal IBC_EngTorqDec_Sub: start 48, 10 bit, little-endian, init-value=0, base-type=uint16, implementation-data-type=DT_IBC_EngTorqDec_Sub, update-indication-bit-position=-1, to MVCU
          signal IBC_EngTorqDecActive_Sub: start 58, 1 bit, little-endian, init-value=0, base-type=uint8, implementation-data-type=DT_IBC_EngTorqDecActive_Sub, update-indication-bit-position=-1, to MVCU
          signal IBC_EngTorqInc_Sub: start 64, 10 bit, little-endian, init-value=0, base-type=uint16, implementation-data-type=DT_IBC_EngTorqInc_Sub, update-indication-bit-position=-1, to MVCU
          signal IBC_EngTorqIncActive_Sub: start 74, 1 bit, little-endian, init-value=0, base-type=uint8, implementation-data-type=DT_IBC_EngTorqIncActive_Sub, update-indication-bit-position=-1, to MVCU
          signal IBC_EngTorqDec_MainR: start 80, 10 bit, little-endian, init-value=0, base-type=uint8, implementation-data-type=DT_IBC_EngTorqDec_MainR, update-indication-bit-position=-1, to MVCU
          signal IBC_EngTorqDecActive_MainR: start 90, 1 bit, little-endian, init-value=0, base-type=uint8, implementation-data-type=DT_IBC_EngTorqDecActive_MainR, update-indication-bit-position=-1, to MVCU
          signal IBC_EngTorqInc_MainR: start 96, 10 bit, little-endian, init-value=0, base-type=uint8, implementation-data-type=DT_IBC_EngTorqInc_MainR, update-indication-bit-position=-1, to MVCU
          signal IBC_EngTorqIncActive_MainR: start 106, 1 bit, little-endian, init-value=0, base-type=uint8, implementation-data-type=DT_IBC_EngTorqIncActive_MainR, update-indication-bit-position=-1, to MVCU
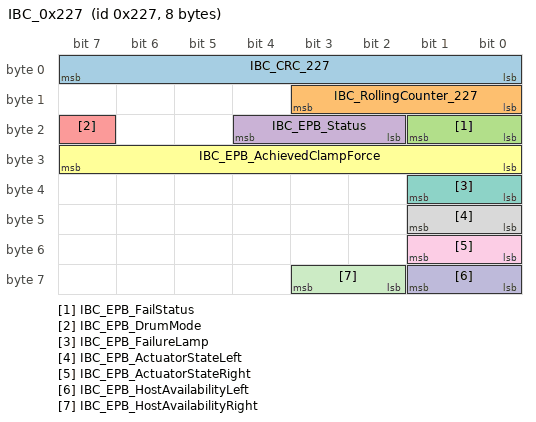
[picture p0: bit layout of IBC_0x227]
      frame IBC_0x227: id 0x227, to MVCU, frame-length=8, can-addressing-mode=STANDARD, can-fd-frame-support=true, can-frame-rx-behavior=CAN-FD
        carries pdu IBC_0x227: packing-byte-order=little-endian, start-position=0, update-indication-bit-position=-1
        pdu IBC_0x227: length=8, transmission-mode-false-timing=cyclic-timing={time-offset=0.0, time-period=0.02}, transmission-mode-true-timing=cyclic-timing={time-offset=0.0, time-period=0.02}
          transmission-mode-conditions:
            {data-filter={data-filter-type=ALWAYS, max=255, min=0, offset=0}, i-signal-in-i-pdu=IBC_CRC_227}
            {data-filter={data-filter-type=ALWAYS, max=15, min=0, offset=0}, i-signal-in-i-pdu=IBC_RollingCounter_227}
            {data-filter={data-filter-type=ALWAYS, max=3, min=0, offset=0}, i-signal-in-i-pdu=IBC_EPB_FailStatus}
            {data-filter={data-filter-type=ALWAYS, max=7, min=0, offset=0}, i-signal-in-i-pdu=IBC_EPB_Status}
            {data-filter={data-filter-type=ALWAYS, max=1, min=0, offset=0}, i-signal-in-i-pdu=IBC_EPB_DrumMode}
            {data-filter={data-filter-type=ALWAYS, max=255, min=0, offset=0}, i-signal-in-i-pdu=IBC_EPB_AchievedClampForce}
            {data-filter={data-filter-type=ALWAYS, max=3, min=0, offset=0}, i-signal-in-i-pdu=IBC_EPB_FailureLamp}
            {data-filter={data-filter-type=ALWAYS, max=3, min=0, offset=0}, i-signal-in-i-pdu=IBC_EPB_ActuatorStateLeft}
            {data-filter={data-filter-type=ALWAYS, max=3, min=0, offset=0}, i-signal-in-i-pdu=IBC_EPB_ActuatorStateRight}
            {data-filter={data-filter-type=ALWAYS, max=3, min=0, offset=0}, i-signal-in-i-pdu=IBC_EPB_HostAvailabilityLeft}
            {data-filter={data-filter-type=ALWAYS, max=3, min=0, offset=0}, i-signal-in-i-pdu=IBC_EPB_HostAvailabilityRight}
          signal IBC_CRC_227: start 0, 8 bit, little-endian, init-value=0, base-type=uint8, implementation-data-type=DT_IBC_CRC_227, update-indication-bit-position=-1, to MVCU
          signal IBC_RollingCounter_227: start 8, 4 bit, little-endian, init-value=0, base-type=uint8, implementation-data-type=DT_IBC_RollingCounter_227, update-indication-bit-position=-1, to MVCU
          signal IBC_EPB_FailStatus: start 16, 2 bit, little-endian, init-value=0, base-type=uint8, implementation-data-type=DT_IBC_EPB_FailStatus, update-indication-bit-position=-1, to MVCU
          signal IBC_EPB_Status: start 18, 3 bit, little-endian, init-value=0, base-type=uint8, implementation-data-type=DT_IBC_EPB_Status, update-indication-bit-position=-1, to MVCU
          signal IBC_EPB_DrumMode: start 23, 1 bit, little-endian, init-value=0, base-type=uint8, implementation-data-type=DT_IBC_EPB_DrumMode, update-indication-bit-position=-1, to MVCU
          signal IBC_EPB_AchievedClampForce: start 24, 8 bit, little-endian, init-value=0, base-type=uint8, implementation-data-type=DT_IBC_EPB_AchievedClampForce, update-indication-bit-position=-1, to MVCU
          signal IBC_EPB_FailureLamp: start 32, 2 bit, little-endian, init-value=0, base-type=uint8, implementation-data-type=DT_IBC_EPB_FailureLamp, update-indication-bit-position=-1, to MVCU
          signal IBC_EPB_ActuatorStateLeft: start 40, 2 bit, little-endian, init-value=0, base-type=uint8, implementation-data-type=DT_IBC_EPB_ActuatorStateLeft, update-indication-bit-position=-1, to MVCU
          signal IBC_EPB_ActuatorStateRight: start 48, 2 bit, little-endian, init-value=0, base-type=uint8, implementation-data-type=DT_IBC_EPB_ActuatorStateRight, update-indication-bit-position=-1, to MVCU
          signal IBC_EPB_HostAvailabilityLeft: start 56, 2 bit, little-endian, init-value=0, base-type=uint8, implementation-data-type=DT_IBC_EPB_HostAvailabilityLeft, update-indication-bit-position=-1, to MVCU
          signal IBC_EPB_HostAvailabilityRight: start 58, 2 bit, little-endian, init-value=0, base-type=uint8, implementation-data-type=DT_IBC_EPB_HostAvailabilityRight, update-indication-bit-position=-1, to MVCU
      frame EPS_0x18D: id 0x18D, to MVCU, frame-length=32, can-addressing-mode=STANDARD, can-fd-frame-support=true, can-frame-rx-behavior=CAN-FD
        carries pdu EPS_0x18D: packing-byte-order=little-endian, start-position=0, update-indication-bit-position=-1
        pdu EPS_0x18D: length=32, transmission-mode-false-timing=cyclic-timing={time-offset=0.0, time-period=0.01}, transmission-mode-true-timing=cyclic-timing={time-offset=0.0, time-period=0.01}
          transmission-mode-conditions:
            {data-filter={data-filter-type=ALWAYS, max=255, min=0, offset=0}, i-signal-in-i-pdu=EPS_CRC_18D}
            {data-filter={data-filter-type=ALWAYS, max=15, min=0, offset=0}, i-signal-in-i-pdu=EPS_RollingCounter_18D}
            {data-filter={data-filter-type=ALWAYS, max=1, min=0, offset=0}, i-signal-in-i-pdu=EPS_Fault}
            {data-filter={data-filter-type=ALWAYS, max=1, min=0, offset=0}, i-signal-in-i-pdu=EPS_CalibrationSts}
            {data-filter={data-filter-type=ALWAYS, max=1, min=0, offset=0}, i-signal-in-i-pdu=EPS_FailureSts}
            {data-filter={data-filter-type=ALWAYS, max=1, min=0, offset=0}, i-signal-in-i-pdu=EPS_SteeringAngleValidData}
            {data-filter={data-filter-type=ALWAYS, max=1, min=0, offset=0}, i-signal-in-i-pdu=EPS_SteeringAngleSpeedValidData}
            {data-filter={data-filter-type=NEW-IS-WITHIN, max=65000, min=0}, i-signal-in-i-pdu=EPS_SteerWheelAngle}
            {data-filter={data-filter-type=ALWAYS, max=254, min=0, offset=0}, i-signal-in-i-pdu=EPS_SteerWheelRotSpd}
            {data-filter={data-filter-type=ALWAYS, max=1, min=0, offset=0}, i-signal-in-i-pdu=EPS_SelfCheckSt}
            {data-filter={data-filter-type=ALWAYS, max=2, min=0, offset=0}, i-signal-in-i-pdu=EPS_AssistanceSts}
          signal EPS_CRC_18D: start 0, 8 bit, little-endian, init-value=0, base-type=uint8, implementation-data-type=DT_EPS_CRC_18D, update-indication-bit-position=-1, to MVCU
          signal EPS_RollingCounter_18D: start 8, 4 bit, little-endian, init-value=0, base-type=uint8, implementation-data-type=DT_EPS_RollingCounter_18D, update-indication-bit-position=-1, to MVCU
          signal EPS_Fault: start 16, 1 bit, little-endian, init-value=0, base-type=uint8, implementation-data-type=DT_EPS_Fault, update-indication-bit-position=-1, to MVCU
          signal EPS_CalibrationSts: start 17, 1 bit, little-endian, init-value=0, base-type=uint8, implementation-data-type=DT_EPS_CalibrationSts, update-indication-bit-position=-1, to MVCU
          signal EPS_FailureSts: start 18, 1 bit, little-endian, init-value=0, base-type=uint8, implementation-data-type=DT_EPS_FailureSts, update-indication-bit-position=-1, to MVCU
          signal EPS_SteeringAngleValidData: start 19, 1 bit, little-endian, init-value=0, base-type=uint8, implementation-data-type=DT_EPS_SteeringAngleValidData, update-indication-bit-position=-1, to MVCU
          signal EPS_SteeringAngleSpeedValidData: start 20, 1 bit, little-endian, init-value=0, base-type=uint8, implementation-data-type=DT_EPS_SteeringAngleSpeedValidData, update-indication-bit-position=-1, to MVCU
          signal EPS_SteerWheelAngle: start 24, 16 bit, little-endian, init-value=0, base-type=uint16, implementation-data-type=DT_EPS_SteerWheelAngle, update-indication-bit-position=-1, to MVCU
          signal EPS_SteerWheelRotSpd: start 40, 8 bit, little-endian, init-value=0, base-type=uint8, implementation-data-type=DT_EPS_SteerWheelRotSpd, update-indication-bit-position=-1, to MVCU
          signal EPS_SelfCheckSt: start 62, 1 bit, little-endian, init-value=0, base-type=uint8, implementation-data-type=DT_EPS_SelfCheckSt, update-indication-bit-position=-1, to MVCU
          signal EPS_AssistanceSts: start 69, 2 bit, little-endian, init-value=0, base-type=uint8, implementation-data-type=DT_EPS_AssistanceSts, update-indication-bit-position=-1, to MVCU
      frame IBC_0x182: id 0x182, to MVCU, frame-length=8, can-addressing-mode=STANDARD, can-fd-frame-support=true, can-frame-rx-behavior=CAN-FD
        carries pdu IBC_0x182: packing-byte-order=little-endian, start-position=0, update-indication-bit-position=-1
        pdu IBC_0x182: length=8, transmission-mode-false-timing=cyclic-timing={time-offset=0.0, time-period=0.02}, transmission-mode-true-timing=cyclic-timing={time-offset=0.0, time-period=0.02}
          transmission-mode-conditions:
            {data-filter={data-filter-type=ALWAYS, max=255, min=0, offset=0}, i-signal-in-i-pdu=IBC_CRC_182}
            {data-filter={data-filter-type=ALWAYS, max=15, min=0, offset=0}, i-signal-in-i-pdu=IBC_RollingCounter_182}
            {data-filter={data-filter-type=NEW-IS-WITHIN, max=45000, min=0, offset=0}, i-signal-in-i-pdu=IBC_VehicleSpeed}
            {data-filter={data-filter-type=ALWAYS, max=1, min=0, offset=0}, i-signal-in-i-pdu=IBC_VehicleSpeedVD}
            {data-filter={data-filter-type=ALWAYS, max=1, min=0, offset=0}, i-signal-in-i-pdu=IBC_ABSActive}
            {data-filter={data-filter-type=ALWAYS, max=1, min=0, offset=0}, i-signal-in-i-pdu=IBC_ABSFailed}
            {data-filter={data-filter-type=ALWAYS, max=1, min=0, offset=0}, i-signal-in-i-pdu=IBC_TCSActive}
            {data-filter={data-filter-type=ALWAYS, max=1, min=0, offset=0}, i-signal-in-i-pdu=IBC_TCSFailed}
            {data-filter={data-filter-type=ALWAYS, max=1, min=0, offset=0}, i-signal-in-i-pdu=IBC_ESCFunctionStatus}
            {data-filter={data-filter-type=ALWAYS, max=1, min=0, offset=0}, i-signal-in-i-pdu=IBC_BrakeForce}
            {data-filter={data-filter-type=ALWAYS, max=1, min=0, offset=0}, i-signal-in-i-pdu=IBC_Vehiclestandstill}
            {data-filter={data-filter-type=ALWAYS, max=1, min=0, offset=0}, i-signal-in-i-pdu=IBC_EBDFailed}
            {data-filter={data-filter-type=ALWAYS, max=1, min=0, offset=0}, i-signal-in-i-pdu=IBC_EBDActive}
            {data-filter={data-filter-type=ALWAYS, max=1, min=0, offset=0}, i-signal-in-i-pdu=IBC_VDCActive}
            {data-filter={data-filter-type=ALWAYS, max=1, min=0, offset=0}, i-signal-in-i-pdu=IBC_VDCFailed}
            {data-filter={data-filter-type=ALWAYS, max=1, min=0, offset=0}, i-signal-in-i-pdu=IBC_EDCActive}
            {data-filter={data-filter-type=ALWAYS, max=1, min=0, offset=0}, i-signal-in-i-pdu=IBC_EDCFailed}
            {data-filter={data-filter-type=ALWAYS, max=1, min=0, offset=0}, i-signal-in-i-pdu=IBC_SystemInitializeStatus}
            {data-filter={data-filter-type=ALWAYS, max=1, min=0, offset=0}, i-signal-in-i-pdu=IBC_BTCSActive}
            {data-filter={data-filter-type=ALWAYS, max=1, min=0, offset=0}, i-signal-in-i-pdu=IBC_ETCSActive}
            {data-filter={data-filter-type=ALWAYS, max=1, min=0, offset=0}, i-signal-in-i-pdu=IBC_ARPActive}
            {data-filter={data-filter-type=ALWAYS, max=1, min=0, offset=0}, i-signal-in-i-pdu=IBC_VCU_DrumMode}
            {data-filter={data-filter-type=ALWAYS, max=1, min=0, offset=0}, i-signal-in-i-pdu=IBC_EscapeModeSts}
            {data-filter={data-filter-type=ALWAYS, max=1, min=0, offset=0}, i-signal-in-i-pdu=IBC_TSAActive}
            {data-filter={data-filter-type=ALWAYS, max=3, min=0, offset=0}, i-signal-in-i-pdu=IBC_TSAStatus}
          signal IBC_CRC_182: start 0, 8 bit, little-endian, init-value=0, base-type=uint8, implementation-data-type=DT_IBC_CRC_182, update-indication-bit-position=-1, to MVCU
          signal IBC_RollingCounter_182: start 8, 4 bit, little-endian, init-value=0, base-type=uint8, implementation-data-type=DT_IBC_RollingCounter_182, update-indication-bit-position=-1, to MVCU
          signal IBC_VehicleSpeed: start 16, 16 bit, little-endian, init-value=0, base-type=uint16, implementation-data-type=DT_IBC_VehicleSpeed, update-indication-bit-position=-1, to MVCU
          signal IBC_VehicleSpeedVD: start 32, 1 bit, little-endian, init-value=0, base-type=uint8, implementation-data-type=DT_IBC_VehicleSpeedVD, update-indication-bit-position=-1, to MVCU
          signal IBC_ABSActive: start 33, 1 bit, little-endian, init-value=0, base-type=uint8, implementation-data-type=DT_IBC_ABSActive, update-indication-bit-position=-1, to MVCU
          signal IBC_ABSFailed: start 34, 1 bit, little-endian, init-value=0, base-type=uint8, implementation-data-type=DT_IBC_ABSFailed, update-indication-bit-position=-1, to MVCU
          signal IBC_TCSActive: start 35, 1 bit, little-endian, init-value=0, base-type=uint8, implementation-data-type=DT_IBC_TCSActive, update-indication-bit-position=-1, to MVCU
          signal IBC_TCSFailed: start 36, 1 bit, little-endian, init-value=0, base-type=uint8, implementation-data-type=DT_IBC_TCSFailed, update-indication-bit-position=-1, to MVCU
          signal IBC_ESCFunctionStatus: start 37, 1 bit, little-endian, init-value=0, base-type=uint8, implementation-data-type=DT_IBC_ESCFunctionStatus, update-indication-bit-position=-1, to MVCU
          signal IBC_BrakeForce: start 38, 1 bit, little-endian, init-value=0, base-type=uint8, implementation-data-type=DT_IBC_BrakeForce, update-indication-bit-position=-1, to MVCU
          signal IBC_Vehiclestandstill: start 39, 1 bit, little-endian, init-value=0, base-type=uint8, implementation-data-type=DT_IBC_Vehiclestandstill, update-indication-bit-position=-1, to MVCU
          signal IBC_EBDFailed: start 40, 1 bit, little-endian, init-value=0, base-type=uint8, implementation-data-type=DT_IBC_EBDFailed, update-indication-bit-position=-1, to MVCU
          signal IBC_EBDActive: start 41, 1 bit, little-endian, init-value=0, base-type=uint8, implementation-data-type=DT_IBC_EBDActive, update-indication-bit-position=-1, to MVCU
          signal IBC_VDCActive: start 42, 1 bit, little-endian, init-value=0, base-type=uint8, implementation-data-type=DT_IBC_VDCActive, update-indication-bit-position=-1, to MVCU
          signal IBC_VDCFailed: start 43, 1 bit, little-endian, init-value=0, base-type=uint8, implementation-data-type=DT_IBC_VDCFailed, update-indication-bit-position=-1, to MVCU
          signal IBC_EDCActive: start 44, 1 bit, little-endian, init-value=0, base-type=uint8, implementation-data-type=DT_IBC_EDCActive, update-indication-bit-position=-1, to MVCU
          signal IBC_EDCFailed: start 45, 1 bit, little-endian, init-value=0, base-type=uint8, implementation-data-type=DT_IBC_EDCFailed, update-indication-bit-position=-1, to MVCU
          signal IBC_SystemInitializeStatus: start 46, 1 bit, little-endian, init-value=0, base-type=uint8, implementation-data-type=DT_IBC_SystemInitializeStatus, update-indication-bit-position=-1, to MVCU
          signal IBC_BTCSActive: start 47, 1 bit, little-endian, init-value=0, base-type=uint8, implementation-data-type=DT_IBC_BTCSActive, update-indication-bit-position=-1, to MVCU
          signal IBC_ETCSActive: start 48, 1 bit, little-endian, init-value=0, base-type=uint8, implementation-data-type=DT_IBC_ETCSActive, update-indication-bit-position=-1, to MVCU
          signal IBC_ARPActive: start 49, 1 bit, little-endian, init-value=0, base-type=uint8, implementation-data-type=DT_IBC_ARPActive, update-indication-bit-position=-1, to MVCU
          signal IBC_VCU_DrumMode: start 50, 1 bit, little-endian, init-value=0, base-type=uint8, implementation-data-type=DT_IBC_VCU_DrumMode, update-indication-bit-position=-1, to MVCU
          signal IBC_EscapeModeSts: start 52, 1 bit, little-endian, init-value=0, base-type=uint8, implementation-data-type=DT_IBC_EscapeModeSts, update-indication-bit-position=-1, to MVCU
          signal IBC_TSAActive: start 53, 1 bit, little-endian, init-value=0, base-type=uint8, implementation-data-type=DT_IBC_TSAActive, update-indication-bit-position=-1, to MVCU
          signal IBC_TSAStatus: start 54, 3 bit, little-endian, init-value=0, base-type=uint8, implementation-data-type=DT_IBC_TSAStatus, update-indication-bit-position=-1, to MVCU
      frame IBC_0x183: id 0x183, to MVCU, frame-length=16, can-addressing-mode=STANDARD, can-fd-frame-support=true, can-frame-rx-behavior=CAN-FD
        carries pdu IBC_0x183: packing-byte-order=little-endian, start-position=0, update-indication-bit-position=-1
        pdu IBC_0x183: length=16, transmission-mode-false-timing=cyclic-timing={time-offset=0.0, time-period=0.02}, transmission-mode-true-timing=cyclic-timing={time-offset=0.0, time-period=0.02}
          transmission-mode-conditions:
            {data-filter={data-filter-type=ALWAYS, max=255, min=0, offset=0}, i-signal-in-i-pdu=IBC_CRC_183}
            {data-filter={data-filter-type=ALWAYS, max=15, min=0, offset=0}, i-signal-in-i-pdu=IBC_RollingCounter_183}
            {data-filter={data-filter-type=NEW-IS-WITHIN, max=32767, min=0, offset=0}, i-signal-in-i-pdu=IBC_RecuBrakeTorqueRequest}
            {data-filter={data-filter-type=ALWAYS, max=3, min=0, offset=0}, i-signal-in-i-pdu=IBC_RecuBrakeTorqueRequest_Q}
            {data-filter={data-filter-type=ALWAYS, max=2, min=0, offset=0}, i-signal-in-i-pdu=IBC_sOutputRodDriverPer_Q}
            {data-filter={data-filter-type=ALWAYS, max=3, min=0, offset=0}, i-signal-in-i-pdu=IBC_BrakePedalApplied_Q}
            {data-filter={data-filter-type=ALWAYS, max=2, min=0, offset=0}, i-signal-in-i-pdu=IBC_HydraTorqTgtAct_Q}
            {data-filter={data-filter-type=NEW-IS-WITHIN, max=32767, min=0, offset=0}, i-signal-in-i-pdu=IBC_HydraTorqTgtAct}
            {data-filter={data-filter-type=ALWAYS, max=1, min=0, offset=0}, i-signal-in-i-pdu=IBC_BrakePedalApplied}
            {data-filter={data-filter-type=ALWAYS, max=100, min=0, offset=0}, i-signal-in-i-pdu=IBC_sOutputRodDriverPer}
            {data-filter={data-filter-type=ALWAYS, max=1, min=0, offset=0}, i-signal-in-i-pdu=IBC_HydraTorqAvailable}
            {data-filter={data-filter-type=ALWAYS, max=7, min=0, offset=0}, i-signal-in-i-pdu=IBC_CtrlMode}
            {data-filter={data-filter-type=ALWAYS, max=1, min=0, offset=0}, i-signal-in-i-pdu=IBC_QDC_HydraTorqTgt}
            {data-filter={data-filter-type=NEW-IS-WITHIN, max=4063, min=0}, i-signal-in-i-pdu=IBC_InPutRodDriver}
            {data-filter={data-filter-type=ALWAYS, max=3, min=0, offset=0}, i-signal-in-i-pdu=IBC_InPutRodDriver_Q}
            {data-filter={data-filter-type=ALWAYS, max=7, min=0, offset=0}, i-signal-in-i-pdu=IBC_SystemAssistedStatus}
            {data-filter={data-filter-type=ALWAYS, max=1, min=0, offset=0}, i-signal-in-i-pdu=IBC_EngTorq_VLC_Vaild}
            {data-filter={data-filter-type=NEW-IS-WITHIN, max=16000, min=0}, i-signal-in-i-pdu=IBC_EngTorq_VLC}
            {data-filter={data-filter-type=NEW-IS-WITHIN, max=32767, min=0}, i-signal-in-i-pdu=IBC_BrkTorq_VLC}
            {data-filter={data-filter-type=ALWAYS, max=1, min=0, offset=0}, i-signal-in-i-pdu=IBC_BrkTorq_VLC_Vaild}
          signal IBC_CRC_183: start 0, 8 bit, little-endian, init-value=0, base-type=uint8, implementation-data-type=DT_IBC_CRC_183, update-indication-bit-position=-1, to MVCU
          signal IBC_RollingCounter_183: start 8, 4 bit, little-endian, init-value=0, base-type=uint8, implementation-data-type=DT_IBC_RollingCounter_183, update-indication-bit-position=-1, to MVCU
          signal IBC_RecuBrakeTorqueRequest: start 16, 15 bit, little-endian, init-value=0, base-type=uint16, implementation-data-type=DT_IBC_RecuBrakeTorqueRequest, update-indication-bit-position=-1, to MVCU
          signal IBC_RecuBrakeTorqueRequest_Q: start 32, 2 bit, little-endian, init-value=0, base-type=uint8, implementation-data-type=DT_IBC_RecuBrakeTorqueRequest_Q, update-indication-bit-position=-1, to MVCU
          signal IBC_sOutputRodDriverPer_Q: start 34, 2 bit, little-endian, init-value=0, base-type=uint8, implementation-data-type=DT_IBC_sOutputRodDriverPer_Q, update-indication-bit-position=-1, to MVCU
          signal IBC_BrakePedalApplied_Q: start 36, 2 bit, little-endian, init-value=0, base-type=uint8, implementation-data-type=DT_IBC_BrakePedalApplied_Q, update-indication-bit-position=-1, to MVCU
          signal IBC_HydraTorqTgtAct_Q: start 38, 2 bit, little-endian, init-value=0, base-type=uint8, implementation-data-type=DT_IBC_HydraTorqTgtAct_Q, update-indication-bit-position=-1, to MVCU
          signal IBC_HydraTorqTgtAct: start 40, 15 bit, little-endian, init-value=0, base-type=uint16, implementation-data-type=DT_IBC_HydraTorqTgtAct, update-indication-bit-position=-1, to MVCU
          signal IBC_BrakePedalApplied: start 55, 1 bit, little-endian, init-value=0, base-type=uint8, implementation-data-type=DT_IBC_BrakePedalApplied, update-indication-bit-position=-1, to MVCU
          signal IBC_sOutputRodDriverPer: start 56, 7 bit, little-endian, init-value=0, base-type=uint8, implementation-data-type=DT_IBC_sOutputRodDriverPer, update-indication-bit-position=-1, to MVCU
          signal IBC_HydraTorqAvailable: start 63, 1 bit, little-endian, init-value=0, base-type=uint8, implementation-data-type=DT_IBC_HydraTorqAvailable, update-indication-bit-position=-1, to MVCU
          signal IBC_CtrlMode: start 64, 3 bit, little-endian, init-value=0, base-type=uint8, implementation-data-type=DT_IBC_CtrlMode, update-indication-bit-position=-1, to MVCU
          signal IBC_QDC_HydraTorqTgt: start 67, 1 bit, little-endian, init-value=0, base-type=uint8, implementation-data-type=DT_IBC_QDC_HydraTorqTgt, update-indication-bit-position=-1, to MVCU
          signal IBC_InPutRodDriver: start 68, 12 bit, little-endian, init-value=0, base-type=uint16, implementation-data-type=DT_IBC_InPutRodDriver, update-indication-bit-position=-1, to MVCU
          signal IBC_InPutRodDriver_Q: start 80, 2 bit, little-endian, init-value=0, base-type=uint8, implementation-data-type=DT_IBC_InPutRodDriver_Q, update-indication-bit-position=-1, to MVCU
          signal IBC_SystemAssistedStatus: start 82, 3 bit, little-endian, init-value=0, base-type=uint8, implementation-data-type=DT_IBC_SystemAssistedStatus, update-indication-bit-position=-1, to MVCU
          signal IBC_EngTorq_VLC_Vaild: start 87, 1 bit, little-endian, init-value=0, base-type=uint8, implementation-data-type=DT_IBC_EngTorq_VLC_Vaild, update-indication-bit-position=-1, to MVCU
          signal IBC_EngTorq_VLC: start 88, 14 bit, little-endian, init-value=0, base-type=uint16, implementation-data-type=DT_IBC_EngTorq_VLC, update-indication-bit-position=-1, to MVCU
          signal IBC_BrkTorq_VLC: start 112, 15 bit, little-endian, init-value=0, base-type=uint16, implementation-data-type=DT_IBC_BrkTorq_VLC, update-indication-bit-position=-1, to MVCU
          signal IBC_BrkTorq_VLC_Vaild: start 127, 1 bit, little-endian, init-value=0, base-type=uint8, implementation-data-type=DT_IBC_BrkTorq_VLC_Vaild, update-indication-bit-position=-1, to MVCU
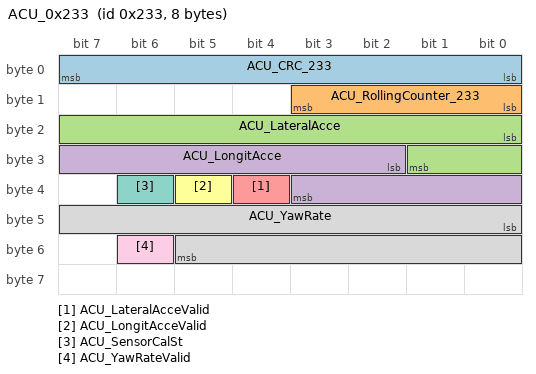
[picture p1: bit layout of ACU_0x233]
      frame ACU_0x233: id 0x233, to MVCU, frame-length=8, can-addressing-mode=STANDARD, can-fd-frame-support=true, can-frame-rx-behavior=CAN-FD
        carries pdu ACU_0x233: packing-byte-order=little-endian, start-position=0, update-indication-bit-position=-1
        pdu ACU_0x233: length=8, transmission-mode-false-timing=cyclic-timing={time-offset=0.0, time-period=0.02}, transmission-mode-true-timing=cyclic-timing={time-offset=0.0, time-period=0.02}
          transmission-mode-conditions:
            {data-filter={data-filter-type=ALWAYS, max=255, min=0, offset=0}, i-signal-in-i-pdu=ACU_CRC_233}
            {data-filter={data-filter-type=ALWAYS, max=15, min=0, offset=0}, i-signal-in-i-pdu=ACU_RollingCounter_233}
            {data-filter={data-filter-type=NEW-IS-WITHIN, max=1021, min=0}, i-signal-in-i-pdu=ACU_LateralAcce}
            {data-filter={data-filter-type=NEW-IS-WITHIN, max=1021, min=0}, i-signal-in-i-pdu=ACU_LongitAcce}
            {data-filter={data-filter-type=ALWAYS, max=1, min=0, offset=0}, i-signal-in-i-pdu=ACU_LateralAcceValid}
            {data-filter={data-filter-type=ALWAYS, max=1, min=0, offset=0}, i-signal-in-i-pdu=ACU_LongitAcceValid}
            {data-filter={data-filter-type=ALWAYS, max=1, min=0, offset=0}, i-signal-in-i-pdu=ACU_SensorCalSt}
            {data-filter={data-filter-type=NEW-IS-WITHIN, max=16382, min=0}, i-signal-in-i-pdu=ACU_YawRate}
            {data-filter={data-filter-type=ALWAYS, max=1, min=0, offset=0}, i-signal-in-i-pdu=ACU_YawRateValid}
          signal ACU_CRC_233: start 0, 8 bit, little-endian, init-value=0, base-type=uint8, implementation-data-type=DT_ACU_CRC_233, update-indication-bit-position=-1, to MVCU
          signal ACU_RollingCounter_233: start 8, 4 bit, little-endian, init-value=0, base-type=uint8, implementation-data-type=DT_ACU_RollingCounter_233, update-indication-bit-position=-1, to MVCU
          signal ACU_LateralAcce: start 16, 10 bit, little-endian, init-value=0, base-type=uint16, implementation-data-type=DT_ACU_LateralAcce, update-indication-bit-position=-1, to MVCU
          signal ACU_LongitAcce: start 26, 10 bit, little-endian, init-value=0, base-type=uint16, implementation-data-type=DT_ACU_LongitAcce, update-indication-bit-position=-1, to MVCU
          signal ACU_LateralAcceValid: start 36, 1 bit, little-endian, init-value=0, base-type=uint8, implementation-data-type=DT_ACU_LateralAcceValid, update-indication-bit-position=-1, to MVCU
          signal ACU_LongitAcceValid: start 37, 1 bit, little-endian, init-value=0, base-type=uint8, implementation-data-type=DT_ACU_LongitAcceValid, update-indication-bit-position=-1, to MVCU
          signal ACU_SensorCalSt: start 38, 1 bit, little-endian, init-value=0, base-type=uint8, implementation-data-type=DT_ACU_SensorCalSt, update-indication-bit-position=-1, to MVCU
          signal ACU_YawRate: start 40, 14 bit, little-endian, init-value=0, base-type=uint16, implementation-data-type=DT_ACU_YawRate, update-indication-bit-position=-1, to MVCU
          signal ACU_YawRateValid: start 54, 1 bit, little-endian, init-value=0, base-type=uint8, implementation-data-type=DT_ACU_YawRateValid, update-indication-bit-position=-1, to MVCU
      frame IBC_0x184: id 0x184, to MVCU, frame-length=32, can-addressing-mode=STANDARD, can-fd-frame-support=true, can-frame-rx-behavior=CAN-FD
        carries pdu IBC_0x184: packing-byte-order=little-endian, start-position=0, update-indication-bit-position=-1
        pdu IBC_0x184: length=32, transmission-mode-false-timing=cyclic-timing={time-offset=0.0, time-period=0.02}, transmission-mode-true-timing=cyclic-timing={time-offset=0.0, time-period=0.02}
          transmission-mode-conditions:
            {data-filter={data-filter-type=ALWAYS, max=255, min=0, offset=0}, i-signal-in-i-pdu=IBC_CRC_184}
            {data-filter={data-filter-type=ALWAYS, max=15, min=0, offset=0}, i-signal-in-i-pdu=IBC_RollingCounter_184}
            {data-filter={data-filter-type=NEW-IS-WITHIN, max=45000, min=0, offset=0}, i-signal-in-i-pdu=IBC_FLWheelSpeedKPH}
            {data-filter={data-filter-type=NEW-IS-WITHIN, max=45000, min=0, offset=0}, i-signal-in-i-pdu=IBC_FRWheelSpeedKPH}
            {data-filter={data-filter-type=NEW-IS-WITHIN, max=45000, min=0, offset=0}, i-signal-in-i-pdu=IBC_RLWheelSpeedKPH}
            {data-filter={data-filter-type=NEW-IS-WITHIN, max=45000, min=0, offset=0}, i-signal-in-i-pdu=IBC_RRWheelSpeedKPH}
            {data-filter={data-filter-type=ALWAYS, max=3, min=0, offset=0}, i-signal-in-i-pdu=IBC_FLWheelDirection}
            {data-filter={data-filter-type=ALWAYS, max=3, min=0, offset=0}, i-signal-in-i-pdu=IBC_FRWheelDirection}
            {data-filter={data-filter-type=ALWAYS, max=3, min=0, offset=0}, i-signal-in-i-pdu=IBC_RLWheelDirection}
            {data-filter={data-filter-type=ALWAYS, max=3, min=0, offset=0}, i-signal-in-i-pdu=IBC_RRWheelDirection}
            {data-filter={data-filter-type=ALWAYS, max=1, min=0, offset=0}, i-signal-in-i-pdu=IBC_FLWheelSpeedVD}
            {data-filter={data-filter-type=ALWAYS, max=1, min=0, offset=0}, i-signal-in-i-pdu=IBC_FRWheelSpeedVD}
            {data-filter={data-filter-type=ALWAYS, max=1, min=0, offset=0}, i-signal-in-i-pdu=IBC_RLWheelSpeedVD}
            {data-filter={data-filter-type=ALWAYS, max=1, min=0, offset=0}, i-signal-in-i-pdu=IBC_RRWheelSpeedVD}
            {data-filter={data-filter-type=NEW-IS-WITHIN, max=4094, min=0, offset=0}, i-signal-in-i-pdu=IBC_FLWheelSpeedRC}
            {data-filter={data-filter-type=NEW-IS-WITHIN, max=4094, min=0, offset=0}, i-signal-in-i-pdu=IBC_FRWheelSpeedRC}
            {data-filter={data-filter-type=NEW-IS-WITHIN, max=4094, min=0, offset=0}, i-signal-in-i-pdu=IBC_RLWheelSpeedRC}
            {data-filter={data-filter-type=NEW-IS-WITHIN, max=4094, min=0, offset=0}, i-signal-in-i-pdu=IBC_RRWheelSpeedRC}
            {data-filter={data-filter-type=ALWAYS, max=7, min=0, offset=0}, i-signal-in-i-pdu=IBC_DiscTemperatureFL}
            {data-filter={data-filter-type=ALWAYS, max=1, min=0, offset=0}, i-signal-in-i-pdu=IBC_DiscTemperatureFLVD}
            {data-filter={data-filter-type=ALWAYS, max=7, min=0, offset=0}, i-signal-in-i-pdu=IBC_DiscTemperatureFR}
            {data-filter={data-filter-type=ALWAYS, max=1, min=0, offset=0}, i-signal-in-i-pdu=IBC_DiscTemperatureFRVD}
            {data-filter={data-filter-type=ALWAYS, max=7, min=0, offset=0}, i-signal-in-i-pdu=IBC_DiscTemperatureRL}
            {data-filter={data-filter-type=ALWAYS, max=1, min=0, offset=0}, i-signal-in-i-pdu=IBC_DiscTemperatureRLVD}
            {data-filter={data-filter-type=ALWAYS, max=7, min=0, offset=0}, i-signal-in-i-pdu=IBC_DiscTemperatureRR}
            {data-filter={data-filter-type=ALWAYS, max=1, min=0, offset=0}, i-signal-in-i-pdu=IBC_DiscTemperatureRRVD}
          signal IBC_CRC_184: start 0, 8 bit, little-endian, init-value=0, base-type=uint8, implementation-data-type=DT_IBC_CRC_184, update-indication-bit-position=-1, to MVCU
          signal IBC_RollingCounter_184: start 8, 4 bit, little-endian, init-value=0, base-type=uint8, implementation-data-type=DT_IBC_RollingCounter_184, update-indication-bit-position=-1, to MVCU
          signal IBC_FLWheelSpeedKPH: start 16, 16 bit, little-endian, init-value=0, base-type=uint16, implementation-data-type=DT_IBC_FLWheelSpeedKPH, update-indication-bit-position=-1, to MVCU
          signal IBC_FRWheelSpeedKPH: start 32, 16 bit, little-endian, init-value=0, base-type=uint16, implementation-data-type=DT_IBC_FRWheelSpeedKPH, update-indication-bit-position=-1, to MVCU
          signal IBC_RLWheelSpeedKPH: start 48, 16 bit, little-endian, init-value=0, base-type=uint16, implementation-data-type=DT_IBC_RLWheelSpeedKPH, update-indication-bit-position=-1, to MVCU
          signal IBC_RRWheelSpeedKPH: start 64, 16 bit, little-endian, init-value=0, base-type=uint16, implementation-data-type=DT_IBC_RRWheelSpeedKPH, update-indication-bit-position=-1, to MVCU
          signal IBC_FLWheelDirection: start 80, 2 bit, little-endian, init-value=0, base-type=uint8, implementation-data-type=DT_IBC_FLWheelDirection, update-indication-bit-position=-1, to MVCU
          signal IBC_FRWheelDirection: start 82, 2 bit, little-endian, init-value=0, base-type=uint8, implementation-data-type=DT_IBC_FRWheelDirection, update-indication-bit-position=-1, to MVCU
          signal IBC_RLWheelDirection: start 84, 2 bit, little-endian, init-value=0, base-type=uint8, implementation-data-type=DT_IBC_RLWheelDirection, update-indication-bit-position=-1, to MVCU
          signal IBC_RRWheelDirection: start 86, 2 bit, little-endian, init-value=0, base-type=uint8, implementation-data-type=DT_IBC_RRWheelDirection, update-indication-bit-position=-1, to MVCU
          signal IBC_FLWheelSpeedVD: start 88, 1 bit, little-endian, init-value=0, base-type=uint8, implementation-data-type=DT_IBC_FLWheelSpeedVD, update-indication-bit-position=-1, to MVCU
          signal IBC_FRWheelSpeedVD: start 89, 1 bit, little-endian, init-value=0, base-type=uint8, implementation-data-type=DT_IBC_FRWheelSpeedVD, update-indication-bit-position=-1, to MVCU
          signal IBC_RLWheelSpeedVD: start 90, 1 bit, little-endian, init-value=0, base-type=uint8, implementation-data-type=DT_IBC_RLWheelSpeedVD, update-indication-bit-position=-1, to MVCU
          signal IBC_RRWheelSpeedVD: start 91, 1 bit, little-endian, init-value=0, base-type=uint8, implementation-data-type=DT_IBC_RRWheelSpeedVD, update-indication-bit-position=-1, to MVCU
          signal IBC_FLWheelSpeedRC: start 92, 12 bit, little-endian, init-value=0, base-type=uint16, implementation-data-type=DT_IBC_FLWheelSpeedRC, update-indication-bit-position=-1, to MVCU
          signal IBC_FRWheelSpeedRC: start 104, 12 bit, little-endian, init-value=0, base-type=uint16, implementation-data-type=DT_IBC_FRWheelSpeedRC, update-indication-bit-position=-1, to MVCU
          signal IBC_RLWheelSpeedRC: start 116, 12 bit, little-endian, init-value=0, base-type=uint16, implementation-data-type=DT_IBC_RLWheelSpeedRC, update-indication-bit-position=-1, to MVCU
          signal IBC_RRWheelSpeedRC: start 128, 12 bit, little-endian, init-value=0, base-type=uint16, implementation-data-type=DT_IBC_RRWheelSpeedRC, update-indication-bit-position=-1, to MVCU
          signal IBC_DiscTemperatureFL: start 184, 3 bit, little-endian, init-value=0, base-type=uint8, implementation-data-type=DT_IBC_DiscTemperatureFL, update-indication-bit-position=-1, to MVCU
          signal IBC_DiscTemperatureFLVD: start 187, 1 bit, little-endian, init-value=0, base-type=uint8, implementation-data-type=DT_IBC_DiscTemperatureFLVD, update-indication-bit-position=-1, to MVCU
          signal IBC_DiscTemperatureFR: start 188, 3 bit, little-endian, init-value=0, base-type=uint8, implementation-data-type=DT_IBC_DiscTemperatureFR, update-indication-bit-position=-1, to MVCU
          signal IBC_DiscTemperatureFRVD: start 191, 1 bit, little-endian, init-value=0, base-type=uint8, implementation-data-type=DT_IBC_DiscTemperatureFRVD, update-indication-bit-position=-1, to MVCU
          signal IBC_DiscTemperatureRL: start 192, 3 bit, little-endian, init-value=0, base-type=uint8, implementation-data-type=DT_IBC_DiscTemperatureRL, update-indication-bit-position=-1, to MVCU
          signal IBC_DiscTemperatureRLVD: start 195, 1 bit, little-endian, init-value=0, base-type=uint8, implementation-data-type=DT_IBC_DiscTemperatureRLVD, update-indication-bit-position=-1, to MVCU
          signal IBC_DiscTemperatureRR: start 196, 3 bit, little-endian, init-value=0, base-type=uint8, implementation-data-type=DT_IBC_DiscTemperatureRR, update-indication-bit-position=-1, to MVCU
          signal IBC_DiscTemperatureRRVD: start 199, 1 bit, little-endian, init-value=0, base-type=uint8, implementation-data-type=DT_IBC_DiscTemperatureRRVD, update-indication-bit-position=-1, to MVCU
      frame FSC_0x142: id 0x142, to MVCU, frame-length=16, can-addressing-mode=STANDARD, can-fd-frame-support=true, can-frame-rx-behavior=CAN-FD
        carries pdu FSC_0x142: packing-byte-order=little-endian, start-position=0, update-indication-bit-position=-1
        pdu FSC_0x142: length=16, transmission-mode-false-timing=cyclic-timing={time-offset=0.0, time-period=0.02}, transmission-mode-true-timing=cyclic-timing={time-offset=0.0, time-period=0.02}
          transmission-mode-conditions:
            {data-filter={data-filter-type=ALWAYS, max=255, min=0, offset=0}, i-signal-in-i-pdu=FSC_CRC_142}
            {data-filter={data-filter-type=ALWAYS, max=15, min=0, offset=0}, i-signal-in-i-pdu=FSC_RollingCounter_142}
            {data-filter={data-filter-type=ALWAYS, max=7, min=0, offset=0}, i-signal-in-i-pdu=FSC_LCC_Mode}
          signal FSC_CRC_142: start 0, 8 bit, little-endian, init-value=0, base-type=uint8, implementation-data-type=DT_FSC_CRC_142, update-indication-bit-position=-1, to MVCU
          signal FSC_RollingCounter_142: start 8, 4 bit, little-endian, init-value=0, base-type=uint8, implementation-data-type=DT_FSC_RollingCounter_142, update-indication-bit-position=-1, to MVCU
          signal FSC_LCC_Mode: start 40, 3 bit, little-endian, init-value=0, base-type=uint8, implementation-data-type=DT_FSC_LCC_Mode, update-indication-bit-position=-1, to MVCU
      frame IBC_0x185: id 0x185, to MVCU, frame-length=16, can-addressing-mode=STANDARD, can-fd-frame-support=true, can-frame-rx-behavior=CAN-FD
        carries pdu IBC_0x185: packing-byte-order=little-endian, start-position=0, update-indication-bit-position=-1
        pdu IBC_0x185: length=16, transmission-mode-false-timing=cyclic-timing={time-offset=0.0, time-period=0.02}, transmission-mode-true-timing=cyclic-timing={time-offset=0.0, time-period=0.02}
          transmission-mode-conditions:
            {data-filter={data-filter-type=ALWAYS, max=255, min=0, offset=0}, i-signal-in-i-pdu=IBC_CRC_185}
            {data-filter={data-filter-type=ALWAYS, max=15, min=0, offset=0}, i-signal-in-i-pdu=IBC_RollingCounter_185}
            {data-filter={data-filter-type=NEW-IS-WITHIN, max=2046, min=0, offset=0}, i-signal-in-i-pdu=IBC_PlungerPressure}
            {data-filter={data-filter-type=ALWAYS, max=1, min=0, offset=0}, i-signal-in-i-pdu=IBC_PlungerPressure_Q}
            {data-filter={data-filter-type=NEW-IS-WITHIN, max=2046, min=0, offset=0}, i-signal-in-i-pdu=IBC_SimulatorPressure}
            {data-filter={data-filter-type=ALWAYS, max=1, min=0, offset=0}, i-signal-in-i-pdu=IBC_SimulatorPressure_Q}
            {data-filter={data-filter-type=ALWAYS, max=3, min=0, offset=0}, i-signal-in-i-pdu=IBC_HMI_WarningOn}
            {data-filter={data-filter-type=ALWAYS, max=1, min=0, offset=0}, i-signal-in-i-pdu=IBC_MIL_WarningOn}
            {data-filter={data-filter-type=NEW-IS-WITHIN, max=1021, min=0}, i-signal-in-i-pdu=IBC_LongitAcceAct}
            {data-filter={data-filter-type=ALWAYS, max=1, min=0, offset=0}, i-signal-in-i-pdu=IBC_LongitAcceActValid}
            {data-filter={data-filter-type=ALWAYS, max=3, min=0, offset=0}, i-signal-in-i-pdu=IBC_brakeFluidWarning}
            {data-filter={data-filter-type=ALWAYS, max=1, min=0, offset=0}, i-signal-in-i-pdu=IBC_SCM_Active}
            {data-filter={data-filter-type=ALWAYS, max=1, min=0, offset=0}, i-signal-in-i-pdu=IBC_SCM_Failed}
            {data-filter={data-filter-type=ALWAYS, max=1, min=0, offset=0}, i-signal-in-i-pdu=IBC_CDPAvailable}
            {data-filter={data-filter-type=ALWAYS, max=1, min=0, offset=0}, i-signal-in-i-pdu=IBC_CDPIntervention}
            {data-filter={data-filter-type=ALWAYS, max=1, min=0, offset=0}, i-signal-in-i-pdu=IBC_AEB_active}
            {data-filter={data-filter-type=ALWAYS, max=1, min=0, offset=0}, i-signal-in-i-pdu=IBC_AEBdecAvailable}
            {data-filter={data-filter-type=ALWAYS, max=3, min=0, offset=0}, i-signal-in-i-pdu=IBC_AVHStatus}
            {data-filter={data-filter-type=ALWAYS, max=1, min=0, offset=0}, i-signal-in-i-pdu=IBC_AVHAvailable}
            {data-filter={data-filter-type=ALWAYS, max=1, min=0, offset=0}, i-signal-in-i-pdu=IBC_HHCActive}
            {data-filter={data-filter-type=ALWAYS, max=1, min=0, offset=0}, i-signal-in-i-pdu=IBC_HHCFailed}
            {data-filter={data-filter-type=ALWAYS, max=1, min=0, offset=0}, i-signal-in-i-pdu=IBC_CDD_Available_APA}
            {data-filter={data-filter-type=ALWAYS, max=1, min=0, offset=0}, i-signal-in-i-pdu=IBC_CDD_Active_APA}
            {data-filter={data-filter-type=ALWAYS, max=1, min=0, offset=0}, i-signal-in-i-pdu=IBC_CDD_Available_ACC}
            {data-filter={data-filter-type=ALWAYS, max=1, min=0, offset=0}, i-signal-in-i-pdu=IBC_CDD_Active_ACC}
            {data-filter={data-filter-type=ALWAYS, max=3, min=0, offset=0}, i-signal-in-i-pdu=IBC_HDCStatus}
            {data-filter={data-filter-type=ALWAYS, max=1, min=0, offset=0}, i-signal-in-i-pdu=IBC_HDCAvailable}
            {data-filter={data-filter-type=ALWAYS, max=3, min=0, offset=0}, i-signal-in-i-pdu=IBC_CSTStatus}
            {data-filter={data-filter-type=ALWAYS, max=1, min=0, offset=0}, i-signal-in-i-pdu=IBC_CSTAvailable}
            {data-filter={data-filter-type=ALWAYS, max=1, min=0, offset=0}, i-signal-in-i-pdu=IBC_VLC_Available_ACC}
            {data-filter={data-filter-type=ALWAYS, max=1, min=0, offset=0}, i-signal-in-i-pdu=IBC_VLC_Active_ACC}
            {data-filter={data-filter-type=ALWAYS, max=1, min=0, offset=0}, i-signal-in-i-pdu=IBC_VLC_Available_APA}
            {data-filter={data-filter-type=ALWAYS, max=1, min=0, offset=0}, i-signal-in-i-pdu=IBC_VLC_Active_APA}
            {data-filter={data-filter-type=ALWAYS, max=3, min=0, offset=0}, i-signal-in-i-pdu=IBC_VehicleHoldStatus}
            {data-filter={data-filter-type=NEW-IS-WITHIN, max=32767, min=0, offset=0}, i-signal-in-i-pdu=IBC_DrvrBrkTqAtWhlsReqd}
          signal IBC_CRC_185: start 0, 8 bit, little-endian, init-value=0, base-type=uint8, implementation-data-type=DT_IBC_CRC_185, update-indication-bit-position=-1, to MVCU
          signal IBC_RollingCounter_185: start 8, 4 bit, little-endian, init-value=0, base-type=uint8, implementation-data-type=DT_IBC_RollingCounter_185, update-indication-bit-position=-1, to MVCU
          signal IBC_PlungerPressure: start 16, 11 bit, little-endian, init-value=0, base-type=uint16, implementation-data-type=DT_IBC_PlungerPressure, update-indication-bit-position=-1, to MVCU
          signal IBC_PlungerPressure_Q: start 27, 1 bit, little-endian, init-value=0, base-type=uint8, implementation-data-type=DT_IBC_PlungerPressure_Q, update-indication-bit-position=-1, to MVCU
          signal IBC_SimulatorPressure: start 28, 11 bit, little-endian, init-value=0, base-type=uint16, implementation-data-type=DT_IBC_SimulatorPressure, update-indication-bit-position=-1, to MVCU
          signal IBC_SimulatorPressure_Q: start 39, 1 bit, little-endian, init-value=0, base-type=uint8, implementation-data-type=DT_IBC_SimulatorPressure_Q, update-indication-bit-position=-1, to MVCU
          signal IBC_HMI_WarningOn: start 45, 2 bit, little-endian, init-value=0, base-type=uint8, implementation-data-type=DT_IBC_HMI_WarningOn, update-indication-bit-position=-1, to MVCU
          signal IBC_MIL_WarningOn: start 47, 1 bit, little-endian, init-value=0, base-type=uint8, implementation-data-type=DT_IBC_MIL_WarningOn, update-indication-bit-position=-1, to MVCU
          signal IBC_LongitAcceAct: start 48, 10 bit, little-endian, init-value=0, base-type=uint16, implementation-data-type=DT_IBC_LongitAcceAct, update-indication-bit-position=-1, to MVCU
          signal IBC_LongitAcceActValid: start 58, 1 bit, little-endian, init-value=0, base-type=uint8, implementation-data-type=DT_IBC_LongitAcceActValid, update-indication-bit-position=-1, to MVCU
          signal IBC_brakeFluidWarning: start 59, 2 bit, little-endian, init-value=0, base-type=uint8, implementation-data-type=DT_IBC_brakeFluidWarning, update-indication-bit-position=-1, to MVCU
          signal IBC_SCM_Active: start 69, 1 bit, little-endian, init-value=0, base-type=uint8, implementation-data-type=DT_IBC_SCM_Active, update-indication-bit-position=-1, to MVCU
          signal IBC_SCM_Failed: start 70, 1 bit, little-endian, init-value=0, base-type=uint8, implementation-data-type=DT_IBC_SCM_Failed, update-indication-bit-position=-1, to MVCU
          signal IBC_CDPAvailable: start 78, 1 bit, little-endian, init-value=0, base-type=uint8, implementation-data-type=DT_IBC_CDPAvailable, update-indication-bit-position=-1, to MVCU
          signal IBC_CDPIntervention: start 79, 1 bit, little-endian, init-value=0, base-type=uint8, implementation-data-type=DT_IBC_CDPIntervention, update-indication-bit-position=-1, to MVCU
          signal IBC_AEB_active: start 80, 1 bit, little-endian, init-value=0, base-type=uint8, implementation-data-type=DT_IBC_AEB_active, update-indication-bit-position=-1, to MVCU
          signal IBC_AEBdecAvailable: start 81, 1 bit, little-endian, init-value=0, base-type=uint8, implementation-data-type=DT_IBC_AEBdecAvailable, update-indication-bit-position=-1, to MVCU
          signal IBC_AVHStatus: start 82, 2 bit, little-endian, init-value=0, base-type=uint8, implementation-data-type=DT_IBC_AVHStatus, update-indication-bit-position=-1, to MVCU
          signal IBC_AVHAvailable: start 84, 1 bit, little-endian, init-value=0, base-type=uint8, implementation-data-type=DT_IBC_AVHAvailable, update-indication-bit-position=-1, to MVCU
          signal IBC_HHCActive: start 85, 1 bit, little-endian, init-value=0, base-type=uint8, implementation-data-type=DT_IBC_HHCActive, update-indication-bit-position=-1, to MVCU
          signal IBC_HHCFailed: start 86, 1 bit, little-endian, init-value=0, base-type=uint8, implementation-data-type=DT_IBC_HHCFailed, update-indication-bit-position=-1, to MVCU
          signal IBC_CDD_Available_APA: start 87, 1 bit, little-endian, init-value=0, base-type=uint8, implementation-data-type=DT_IBC_CDD_Available_APA, update-indication-bit-position=-1, to MVCU
          signal IBC_CDD_Active_APA: start 88, 1 bit, little-endian, init-value=0, base-type=uint8, implementation-data-type=DT_IBC_CDD_Active_APA, update-indication-bit-position=-1, to MVCU
          signal IBC_CDD_Available_ACC: start 90, 1 bit, little-endian, init-value=0, base-type=uint8, implementation-data-type=DT_IBC_CDD_Available_ACC, update-indication-bit-position=-1, to MVCU
          signal IBC_CDD_Active_ACC: start 91, 1 bit, little-endian, init-value=0, base-type=uint8, implementation-data-type=DT_IBC_CDD_Active_ACC, update-indication-bit-position=-1, to MVCU
          signal IBC_HDCStatus: start 94, 2 bit, little-endian, init-value=0, base-type=uint8, implementation-data-type=DT_IBC_HDCStatus, update-indication-bit-position=-1, to MVCU
          signal IBC_HDCAvailable: start 96, 1 bit, little-endian, init-value=0, base-type=uint8, implementation-data-type=DT_IBC_HDCAvailable, update-indication-bit-position=-1, to MVCU
          signal IBC_CSTStatus: start 97, 2 bit, little-endian, init-value=0, base-type=uint8, implementation-data-type=DT_IBC_CSTStatus, update-indication-bit-position=-1, to MVCU
          signal IBC_CSTAvailable: start 99, 1 bit, little-endian, init-value=0, base-type=uint8, implementation-data-type=DT_IBC_CSTAvailable, update-indication-bit-position=-1, to MVCU
          signal IBC_VLC_Available_ACC: start 100, 1 bit, little-endian, init-value=0, base-type=uint8, implementation-data-type=DT_IBC_VLC_Available_ACC, update-indication-bit-position=-1, to MVCU
          signal IBC_VLC_Active_ACC: start 101, 1 bit, little-endian, init-value=0, base-type=uint8, implementation-data-type=DT_IBC_VLC_Active_ACC, update-indication-bit-position=-1, to MVCU
          signal IBC_VLC_Available_APA: start 102, 1 bit, little-endian, init-value=0, base-type=uint8, implementation-data-type=DT_IBC_VLC_Available_APA, update-indication-bit-position=-1, to MVCU
          signal IBC_VLC_Active_APA: start 103, 1 bit, little-endian, init-value=0, base-type=uint8, implementation-data-type=DT_IBC_VLC_Active_APA, update-indication-bit-position=-1, to MVCU
          signal IBC_VehicleHoldStatus: start 104, 2 bit, little-endian, init-value=0, base-type=uint8, implementation-data-type=DT_IBC_VehicleHoldStatus, update-indication-bit-position=-1, to MVCU
          signal IBC_DrvrBrkTqAtWhlsReqd: start 113, 15 bit, little-endian, init-value=0, base-type=uint16, implementation-data-type=DT_IBC_DrvrBrkTqAtWhlsReqd, update-indication-bit-position=-1, to MVCU
      frame ACU_0x2A3: id 0x2A3, to MVCU, frame-length=16, can-addressing-mode=STANDARD, can-fd-frame-support=true, can-frame-rx-behavior=CAN-FD
        carries pdu ACU_0x2A3: packing-byte-order=little-endian, start-position=0, update-indication-bit-position=-1
        pdu ACU_0x2A3: length=16, transmission-mode-false-timing=cyclic-timing={time-offset=0.0, time-period=0.1}, transmission-mode-true-timing=cyclic-timing={time-offset=0.0, time-period=0.1}
          transmission-mode-conditions:
            {data-filter={data-filter-type=ALWAYS, max=255, min=0, offset=0}, i-signal-in-i-pdu=ACU_CRC_2A3}
            {data-filter={data-filter-type=ALWAYS, max=1, min=0, offset=0}, i-signal-in-i-pdu=ACU_Trigger}
            {data-filter={data-filter-type=ALWAYS, max=15, min=0, offset=0}, i-signal-in-i-pdu=ACU_RollingCounter_2A3}
            {data-filter={data-filter-type=ALWAYS, max=1, min=0, offset=0}, i-signal-in-i-pdu=ACU_TotalCrashOutputSts}
            {data-filter={data-filter-type=ALWAYS, max=1, min=0, offset=0}, i-signal-in-i-pdu=ACU_SelfCheckSt}
            {data-filter={data-filter-type=ALWAYS, max=3, min=0, offset=0}, i-signal-in-i-pdu=ACU_FLSeatBeltRSt}
            {data-filter={data-filter-type=ALWAYS, max=3, min=0, offset=0}, i-signal-in-i-pdu=ACU_FRSeatBeltRSt}
          signal ACU_CRC_2A3: start 0, 8 bit, little-endian, init-value=0, base-type=uint8, implementation-data-type=DT_ACU_CRC_2A3, update-indication-bit-position=-1, to MVCU
          signal ACU_Trigger: start 88, 1 bit, little-endian, init-value=0, base-type=uint8, implementation-data-type=DT_ACU_Trigger, update-indication-bit-position=-1, to MVCU
          signal ACU_RollingCounter_2A3: start 8, 4 bit, little-endian, init-value=0, base-type=uint8, implementation-data-type=DT_ACU_RollingCounter_2A3, update-indication-bit-position=-1, to MVCU
          signal ACU_TotalCrashOutputSts: start 16, 1 bit, little-endian, init-value=0, base-type=uint8, implementation-data-type=DT_ACU_TotalCrashOutputSts, update-indication-bit-position=-1, to MVCU
          signal ACU_SelfCheckSt: start 28, 1 bit, little-endian, init-value=0, base-type=uint8, implementation-data-type=DT_ACU_SelfCheckSt, update-indication-bit-position=-1, to MVCU
          signal ACU_FLSeatBeltRSt: start 30, 2 bit, little-endian, init-value=0, base-type=uint8, implementation-data-type=DT_ACU_FLSeatBeltRSt, update-indication-bit-position=-1, to MVCU
          signal ACU_FRSeatBeltRSt: start 32, 2 bit, little-endian, init-value=0, base-type=uint8, implementation-data-type=DT_ACU_FRSeatBeltRSt, update-indication-bit-position=-1, to MVCU
      frame ICU_0x24D: id 0x24D, to MVCU, frame-length=32, can-addressing-mode=STANDARD, can-fd-frame-support=true, can-frame-rx-behavior=CAN-FD
        carries pdu ICU_0x24D: packing-byte-order=little-endian, start-position=0, update-indication-bit-position=-1
        pdu ICU_0x24D: length=32, transmission-mode-false-timing=cyclic-timing={time-offset=0.0, time-period=0.1}, transmission-mode-true-timing=cyclic-timing={time-offset=0.0, time-period=0.1}
          transmission-mode-conditions:
            {data-filter={data-filter-type=ALWAYS, max=255, min=0, offset=0}, i-signal-in-i-pdu=ICU_CRC_24D}
            {data-filter={data-filter-type=ALWAYS, max=3, min=0, offset=0}, i-signal-in-i-pdu=ICU_SpeedConversionCoefficient}
            {data-filter={data-filter-type=ALWAYS, max=15, min=0, offset=0}, i-signal-in-i-pdu=ICU_RollingCounter_24D}
            {data-filter={data-filter-type=ALWAYS, max=1, min=0, offset=0}, i-signal-in-i-pdu=ICU_CCSFunctionStatus}
            {data-filter={data-filter-type=NEW-IS-WITHIN, max=45000, min=0, offset=0}, i-signal-in-i-pdu=ICU_CruiseVehicleSpeedCtl}
            {data-filter={data-filter-type=NEW-IS-WITHIN, max=450, min=0, offset=0}, i-signal-in-i-pdu=ICU_VehicleScreenSpeed}
            {data-filter={data-filter-type=ALWAYS, max=1, min=0, offset=0}, i-signal-in-i-pdu=ICU_VehicleSpeedUnit}
            {data-filter={data-filter-type=ALWAYS, max=1, min=0, offset=0}, i-signal-in-i-pdu=ICU_ACCFunctionStatus}
            {data-filter={data-filter-type=ALWAYS, max=1, min=0, offset=0}, i-signal-in-i-pdu=ICU_LCCFunctionStatus}
            {data-filter={data-filter-type=ALWAYS, max=1, min=0, offset=0}, i-signal-in-i-pdu=IVI_LPedalMode}
          signal ICU_CRC_24D: start 0, 8 bit, little-endian, init-value=0, base-type=uint8, implementation-data-type=DT_ICU_CRC_24D, update-indication-bit-position=-1, to MVCU
          signal ICU_SpeedConversionCoefficient: start 154, 2 bit, little-endian, init-value=0, base-type=uint8, implementation-data-type=DT_ICU_SpeedConversionCoefficient, update-indication-bit-position=-1, to MVCU
          signal ICU_RollingCounter_24D: start 8, 4 bit, little-endian, init-value=0, base-type=uint8, implementation-data-type=DT_ICU_RollingCounter_24D, update-indication-bit-position=-1, to MVCU
          signal ICU_CCSFunctionStatus: start 39, 1 bit, little-endian, init-value=0, base-type=uint8, implementation-data-type=DT_ICU_CCSFunctionStatus, update-indication-bit-position=-1, to MVCU
          signal ICU_CruiseVehicleSpeedCtl: start 64, 16 bit, little-endian, init-value=0, base-type=uint16, implementation-data-type=DT_ICU_CruiseVehicleSpeedCtl, update-indication-bit-position=-1, to MVCU
          signal ICU_VehicleScreenSpeed: start 80, 9 bit, little-endian, init-value=0, base-type=uint16, implementation-data-type=DT_ICU_VehicleScreenSpeed, update-indication-bit-position=-1, to MVCU
          signal ICU_VehicleSpeedUnit: start 89, 1 bit, little-endian, init-value=0, base-type=uint8, implementation-data-type=DT_ICU_VehicleSpeedUnit, update-indication-bit-position=-1, to MVCU
          signal ICU_ACCFunctionStatus: start 131, 1 bit, little-endian, init-value=0, base-type=uint8, implementation-data-type=DT_ICU_ACCFunctionStatus, update-indication-bit-position=-1, to MVCU
          signal ICU_LCCFunctionStatus: start 132, 1 bit, little-endian, init-value=0, base-type=uint8, implementation-data-type=DT_ICU_LCCFunctionStatus, update-indication-bit-position=-1, to MVCU
          signal IVI_LPedalMode: start 133, 1 bit, little-endian, init-value=0, base-type=uint8, implementation-data-type=DT_IVI_LPedalMode, update-indication-bit-position=-1, to MVCU
      frame HPCBCM_0x290: id 0x290, to MVCU, frame-length=8, can-addressing-mode=STANDARD, can-fd-frame-support=true, can-frame-rx-behavior=CAN-FD
        carries pdu HPCBCM_0x290: packing-byte-order=little-endian, start-position=0, update-indication-bit-position=-1
        pdu HPCBCM_0x290: length=8, transmission-mode-false-timing=cyclic-timing={time-offset=0.0, time-period=0.02}, transmission-mode-true-timing=cyclic-timing={time-offset=0.0, time-period=0.02}
          transmission-mode-conditions:
            {data-filter={data-filter-type=ALWAYS, max=255, min=0, offset=0}, i-signal-in-i-pdu=BCM_CRC_290}
            {data-filter={data-filter-type=ALWAYS, max=1, min=0, offset=0}, i-signal-in-i-pdu=BCM_RRDoorSts_ID290_CCAN}
            {data-filter={data-filter-type=ALWAYS, max=1, min=0, offset=0}, i-signal-in-i-pdu=BCM_RLDoorSts_ID290_CCAN}
            {data-filter={data-filter-type=ALWAYS, max=15, min=0, offset=0}, i-signal-in-i-pdu=BCM_RollingCounter_290}
            {data-filter={data-filter-type=ALWAYS, max=1, min=0, offset=0}, i-signal-in-i-pdu=BCM_HazardSwtSts}
            {data-filter={data-filter-type=ALWAYS, max=3, min=0, offset=0}, i-signal-in-i-pdu=BCM_DrOC_PPD_Status}
            {data-filter={data-filter-type=ALWAYS, max=3, min=0, offset=0}, i-signal-in-i-pdu=BCM_FLOC_PPD_Status}
            {data-filter={data-filter-type=ALWAYS, max=3, min=0, offset=0}, i-signal-in-i-pdu=BCM_FROC_PPD_Status}
            {data-filter={data-filter-type=ALWAYS, max=1, min=0, offset=0}, i-signal-in-i-pdu=BCM_DriverDoorSts_ID290_CCAN}
            {data-filter={data-filter-type=ALWAYS, max=1, min=0, offset=0}, i-signal-in-i-pdu=BCM_DriverDoorSts_VD}
            {data-filter={data-filter-type=ALWAYS, max=1, min=0, offset=0}, i-signal-in-i-pdu=BCM_FLDoorSts_ID290_CCAN}
            {data-filter={data-filter-type=ALWAYS, max=1, min=0, offset=0}, i-signal-in-i-pdu=BCM_FRDoorSts_ID290_CCAN}
            {data-filter={data-filter-type=ALWAYS, max=1, min=0, offset=0}, i-signal-in-i-pdu=BCM_BackDoorSts_ID290_CCAN}
            {data-filter={data-filter-type=ALWAYS, max=1, min=0, offset=0}, i-signal-in-i-pdu=BCM_FrontCoverSts}
            {data-filter={data-filter-type=ALWAYS, max=1, min=0, offset=0}, i-signal-in-i-pdu=BCM_HazardSwtOpenSts}
            {data-filter={data-filter-type=ALWAYS, max=3, min=0, offset=0}, i-signal-in-i-pdu=BCM_BrakeFluidLevel}
            {data-filter={data-filter-type=ALWAYS, max=1, min=0, offset=0}, i-signal-in-i-pdu=BCM_ON2BRelaySts_ID290_CCAN}
            {data-filter={data-filter-type=ALWAYS, max=1, min=0, offset=0}, i-signal-in-i-pdu=BCM_ON2CRelaySts_ID290_CCAN}
            {data-filter={data-filter-type=ALWAYS, max=3, min=0, offset=0}, i-signal-in-i-pdu=BCM_AlarmMode_C}
          signal BCM_CRC_290: start 0, 8 bit, little-endian, init-value=0, base-type=uint8, implementation-data-type=DT_BCM_CRC_290, update-indication-bit-position=-1, to MVCU
          signal BCM_RRDoorSts_ID290_CCAN: start 49, 1 bit, little-endian, init-value=0, base-type=uint8, implementation-data-type=DT_BCM_RRDoorSts_ID290_CCAN, update-indication-bit-position=-1, to MVCU
          signal BCM_RLDoorSts_ID290_CCAN: start 48, 1 bit, little-endian, init-value=0, base-type=uint8, implementation-data-type=DT_BCM_RLDoorSts_ID290_CCAN, update-indication-bit-position=-1, to MVCU
          signal BCM_RollingCounter_290: start 8, 4 bit, little-endian, init-value=0, base-type=uint8, implementation-data-type=DT_BCM_RollingCounter_290, update-indication-bit-position=-1, to MVCU
          signal BCM_HazardSwtSts: start 23, 1 bit, little-endian, init-value=0, base-type=uint8, implementation-data-type=DT_BCM_HazardSwtSts, update-indication-bit-position=-1, to MVCU
          signal BCM_DrOC_PPD_Status: start 28, 2 bit, little-endian, init-value=0, base-type=uint8, implementation-data-type=DT_BCM_DrOC_PPD_Status, update-indication-bit-position=-1, to MVCU
          signal BCM_FLOC_PPD_Status: start 30, 2 bit, little-endian, init-value=0, base-type=uint8, implementation-data-type=DT_BCM_FLOC_PPD_Status, update-indication-bit-position=-1, to MVCU
          signal BCM_FROC_PPD_Status: start 32, 2 bit, little-endian, init-value=0, base-type=uint8, implementation-data-type=DT_BCM_FROC_PPD_Status, update-indication-bit-position=-1, to MVCU
          signal BCM_DriverDoorSts_ID290_CCAN: start 44, 1 bit, little-endian, init-value=0, base-type=uint8, implementation-data-type=DT_BCM_DriverDoorSts_ID290_CCAN, update-indication-bit-position=-1, to MVCU
          signal BCM_DriverDoorSts_VD: start 45, 1 bit, little-endian, init-value=0, base-type=uint8, implementation-data-type=DT_BCM_DriverDoorSts_VD, update-indication-bit-position=-1, to MVCU
          signal BCM_FLDoorSts_ID290_CCAN: start 46, 1 bit, little-endian, init-value=0, base-type=uint8, implementation-data-type=DT_BCM_FLDoorSts_ID290_CCAN, update-indication-bit-position=-1, to MVCU
          signal BCM_FRDoorSts_ID290_CCAN: start 47, 1 bit, little-endian, init-value=0, base-type=uint8, implementation-data-type=DT_BCM_FRDoorSts_ID290_CCAN, update-indication-bit-position=-1, to MVCU
          signal BCM_BackDoorSts_ID290_CCAN: start 50, 1 bit, little-endian, init-value=0, base-type=uint8, implementation-data-type=DT_BCM_BackDoorSts_ID290_CCAN, update-indication-bit-position=-1, to MVCU
          signal BCM_FrontCoverSts: start 51, 1 bit, little-endian, init-value=0, base-type=uint8, implementation-data-type=DT_BCM_FrontCoverSts, update-indication-bit-position=-1, to MVCU
          signal BCM_HazardSwtOpenSts: start 52, 1 bit, little-endian, init-value=0, base-type=uint8, implementation-data-type=DT_BCM_HazardSwtOpenSts, update-indication-bit-position=-1, to MVCU
          signal BCM_BrakeFluidLevel: start 53, 2 bit, little-endian, init-value=0, base-type=uint8, implementation-data-type=DT_BCM_BrakeFluidLevel, update-indication-bit-position=-1, to MVCU
          signal BCM_ON2BRelaySts_ID290_CCAN: start 57, 1 bit, little-endian, init-value=0, base-type=uint8, implementation-data-type=DT_BCM_ON2BRelaySts_ID290_CCAN, update-indication-bit-position=-1, to MVCU
          signal BCM_ON2CRelaySts_ID290_CCAN: start 58, 1 bit, little-endian, init-value=0, base-type=uint8, implementation-data-type=DT_BCM_ON2CRelaySts_ID290_CCAN, update-indication-bit-position=-1, to MVCU
          signal BCM_AlarmMode_C: start 61, 2 bit, little-endian, init-value=0, base-type=uint8, implementation-data-type=DT_BCM_AlarmMode_C, update-indication-bit-position=-1, to MVCU
      frame IVI_0x331: id 0x331, to MVCU, frame-length=16, can-addressing-mode=STANDARD, can-fd-frame-support=true, can-frame-rx-behavior=CAN-FD
        carries pdu IVI_0x331: packing-byte-order=little-endian, start-position=0, update-indication-bit-position=-1
        pdu IVI_0x331: length=16, transmission-mode-false-timing=cyclic-timing={time-offset=0.0, time-period=0.2}, transmission-mode-true-timing=cyclic-timing={time-offset=0.0, time-period=0.2}
          transmission-mode-conditions:
            {data-filter={data-filter-type=ALWAYS, max=255, min=0, offset=0}, i-signal-in-i-pdu=IVI_CRC_331}
            {data-filter={data-filter-type=ALWAYS, max=15, min=0, offset=0}, i-signal-in-i-pdu=IVI_RollingCounter_331}
            {data-filter={data-filter-type=ALWAYS, max=3, min=0, offset=0}, i-signal-in-i-pdu=IVI_EPBRequst}
            {data-filter={data-filter-type=ALWAYS, max=7, min=0, offset=0}, i-signal-in-i-pdu=IVI_TerrainMatchMode}
            {data-filter={data-filter-type=ALWAYS, max=1, min=0, offset=0}, i-signal-in-i-pdu=IVI_LPedalModeSW}
            {data-filter={data-filter-type=ALWAYS, max=3, min=0, offset=0}, i-signal-in-i-pdu=IVI_AVHSw_X}
            {data-filter={data-filter-type=ALWAYS, max=3, min=0, offset=0}, i-signal-in-i-pdu=IVI_ESCSw_X}
            {data-filter={data-filter-type=ALWAYS, max=3, min=0, offset=0}, i-signal-in-i-pdu=IVI_HDCSw_X}
            {data-filter={data-filter-type=ALWAYS, max=3, min=0, offset=0}, i-signal-in-i-pdu=IVI_CSTSw_X}
            {data-filter={data-filter-type=ALWAYS, max=7, min=0, offset=0}, i-signal-in-i-pdu=IVI_AutoAllRoad}
            {data-filter={data-filter-type=ALWAYS, max=1, min=0, offset=0}, i-signal-in-i-pdu=IVI_CampingMode_SW}
            {data-filter={data-filter-type=ALWAYS, max=3, min=0, offset=0}, i-signal-in-i-pdu=IVI_BraPedMod}
            {data-filter={data-filter-type=ALWAYS, max=1, min=0, offset=0}, i-signal-in-i-pdu=IVI_SlowspeedSmartCtrl}
            {data-filter={data-filter-type=ALWAYS, max=1, min=0, offset=0}, i-signal-in-i-pdu=IVI_TrailerModeCtrl}
            {data-filter={data-filter-type=ALWAYS, max=1, min=0, offset=0}, i-signal-in-i-pdu=IVI_EscapeMode_SW}
            {data-filter={data-filter-type=ALWAYS, max=3, min=0, offset=0}, i-signal-in-i-pdu=IVI_PowerSavingModeReq}
            {data-filter={data-filter-type=ALWAYS, max=1, min=0, offset=0}, i-signal-in-i-pdu=IVI_SelfAdaptionDriveSW}
            {data-filter={data-filter-type=ALWAYS, max=1, min=0, offset=0}, i-signal-in-i-pdu=IVI_CmpUTurnStartUI}
            {data-filter={data-filter-type=ALWAYS, max=7, min=0, offset=0}, i-signal-in-i-pdu=IVI_CmpUTurnLockWhlUI}
            {data-filter={data-filter-type=ALWAYS, max=3, min=0, offset=0}, i-signal-in-i-pdu=IVI_CmpUTurnTarDirUI}
            {data-filter={data-filter-type=ALWAYS, max=511, min=0, offset=0}, i-signal-in-i-pdu=IVI_CmpUTurnTarAngleUI}
            {data-filter={data-filter-type=ALWAYS, max=3, min=0, offset=0}, i-signal-in-i-pdu=IVI_CmpUTurnReq}
          signal IVI_CRC_331: start 0, 8 bit, little-endian, init-value=0, base-type=uint8, implementation-data-type=DT_IVI_CRC_331, update-indication-bit-position=-1, to MVCU
          signal IVI_RollingCounter_331: start 8, 4 bit, little-endian, init-value=0, base-type=uint8, implementation-data-type=DT_IVI_RollingCounter_331, update-indication-bit-position=-1, to MVCU
          signal IVI_EPBRequst: start 22, 2 bit, little-endian, init-value=0, base-type=uint8, implementation-data-type=DT_IVI_EPBRequst, update-indication-bit-position=-1, to MVCU
          signal IVI_TerrainMatchMode: start 24, 3 bit, little-endian, init-value=0, base-type=uint8, implementation-data-type=DT_IVI_TerrainMatchMode, update-indication-bit-position=-1, to MVCU
          signal IVI_LPedalModeSW: start 27, 1 bit, little-endian, init-value=0, base-type=uint8, implementation-data-type=DT_IVI_LPedalModeSW, update-indication-bit-position=-1, to MVCU
          signal IVI_AVHSw_X: start 28, 2 bit, little-endian, init-value=0, base-type=uint8, implementation-data-type=DT_IVI_AVHSw_X, update-indication-bit-position=-1, to MVCU
          signal IVI_ESCSw_X: start 30, 2 bit, little-endian, init-value=0, base-type=uint8, implementation-data-type=DT_IVI_ESCSw_X, update-indication-bit-position=-1, to MVCU
          signal IVI_HDCSw_X: start 32, 2 bit, little-endian, init-value=0, base-type=uint8, implementation-data-type=DT_IVI_HDCSw_X, update-indication-bit-position=-1, to MVCU
          signal IVI_CSTSw_X: start 34, 2 bit, little-endian, init-value=0, base-type=uint8, implementation-data-type=DT_IVI_CSTSw_X, update-indication-bit-position=-1, to MVCU
          signal IVI_AutoAllRoad: start 65, 3 bit, little-endian, init-value=0, base-type=uint8, implementation-data-type=DT_IVI_AutoAllRoad, update-indication-bit-position=-1, to MVCU
          signal IVI_CampingMode_SW: start 75, 1 bit, little-endian, init-value=0, base-type=uint8, implementation-data-type=DT_IVI_CampingMode_SW, update-indication-bit-position=-1, to MVCU
          signal IVI_BraPedMod: start 76, 2 bit, little-endian, init-value=0, base-type=uint8, implementation-data-type=DT_IVI_BraPedMod, update-indication-bit-position=-1, to MVCU
          signal IVI_SlowspeedSmartCtrl: start 78, 1 bit, little-endian, init-value=0, base-type=uint8, implementation-data-type=DT_IVI_SlowspeedSmartCtrl, update-indication-bit-position=-1, to MVCU
          signal IVI_TrailerModeCtrl: start 79, 1 bit, little-endian, init-value=0, base-type=uint8, implementation-data-type=DT_IVI_TrailerModeCtrl, update-indication-bit-position=-1, to MVCU
          signal IVI_EscapeMode_SW: start 81, 1 bit, little-endian, init-value=0, base-type=uint8, implementation-data-type=DT_IVI_EscapeMode_SW, update-indication-bit-position=-1, to MVCU
          signal IVI_PowerSavingModeReq: start 85, 2 bit, little-endian, init-value=0, base-type=uint8, implementation-data-type=DT_IVI_PowerSavingModeReq, update-indication-bit-position=-2, to MVCU
          signal IVI_SelfAdaptionDriveSW: start 87, 1 bit, little-endian, init-value=0, base-type=uint8, implementation-data-type=DT_IVI_SelfAdaptionDriveSW, update-indication-bit-position=-1, to MVCU
          signal IVI_CmpUTurnStartUI: start 89, 1 bit, little-endian, init-value=0, base-type=uint8, implementation-data-type=DT_IVI_CmpUTurnStartUI, update-indication-bit-position=-1, to MVCU
          signal IVI_CmpUTurnLockWhlUI: start 90, 3 bit, little-endian, init-value=0, base-type=uint8, implementation-data-type=DT_IVI_CmpUTurnLockWhlUI, update-indication-bit-position=-1, to MVCU
          signal IVI_CmpUTurnTarDirUI: start 93, 2 bit, little-endian, init-value=0, base-type=uint8, implementation-data-type=DT_IVI_CmpUTurnTarDirUI, update-indication-bit-position=-1, to MVCU
          signal IVI_CmpUTurnTarAngleUI: start 95, 9 bit, little-endian, init-value=0, base-type=uint16, implementation-data-type=DT_IVI_CmpUTurnTarAngleUI, update-indication-bit-position=-1, to MVCU
          signal IVI_CmpUTurnReq: start 104, 2 bit, little-endian, init-value=0, base-type=uint8, implementation-data-type=DT_IVI_CmpUTurnReq, update-indication-bit-position=-1, to MVCU
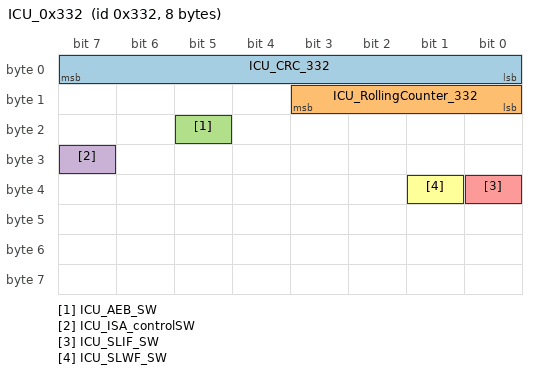
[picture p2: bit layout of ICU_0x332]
      frame ICU_0x332: id 0x332, to MVCU, frame-length=8, can-addressing-mode=STANDARD, can-fd-frame-support=true, can-frame-rx-behavior=CAN-FD
        carries pdu ICU_0x332: packing-byte-order=little-endian, start-position=0, update-indication-bit-position=-1
        pdu ICU_0x332: length=8, transmission-mode-false-timing=cyclic-timing={time-offset=0.0, time-period=0.2}, transmission-mode-true-timing=cyclic-timing={time-offset=0.0, time-period=0.2}
          transmission-mode-conditions:
            {data-filter={data-filter-type=ALWAYS, max=255, min=0, offset=0}, i-signal-in-i-pdu=ICU_CRC_332}
            {data-filter={data-filter-type=ALWAYS, max=15, min=0, offset=0}, i-signal-in-i-pdu=ICU_RollingCounter_332}
            {data-filter={data-filter-type=ALWAYS, max=1, min=0, offset=0}, i-signal-in-i-pdu=ICU_AEB_SW}
            {data-filter={data-filter-type=ALWAYS, max=1, min=0, offset=0}, i-signal-in-i-pdu=ICU_ISA_controlSW}
            {data-filter={data-filter-type=ALWAYS, max=1, min=0, offset=0}, i-signal-in-i-pdu=ICU_SLIF_SW}
            {data-filter={data-filter-type=ALWAYS, max=1, min=0, offset=0}, i-signal-in-i-pdu=ICU_SLWF_SW}
          signal ICU_CRC_332: start 0, 8 bit, little-endian, init-value=0, base-type=uint8, implementation-data-type=DT_ICU_CRC_332, update-indication-bit-position=-1, to MVCU
          signal ICU_RollingCounter_332: start 8, 4 bit, little-endian, init-value=0, base-type=uint8, implementation-data-type=DT_ICU_RollingCounter_332, update-indication-bit-position=-1, to MVCU
          signal ICU_AEB_SW: start 21, 1 bit, little-endian, init-value=0, base-type=uint8, implementation-data-type=DT_ICU_AEB_SW, update-indication-bit-position=-1, to MVCU
          signal ICU_ISA_controlSW: start 31, 1 bit, little-endian, init-value=0, base-type=uint8, implementation-data-type=DT_ICU_ISA_controlSW, update-indication-bit-position=-1, to MVCU
          signal ICU_SLIF_SW: start 32, 1 bit, little-endian, init-value=0, base-type=uint8, implementation-data-type=DT_ICU_SLIF_SW, update-indication-bit-position=-1, to MVCU
          signal ICU_SLWF_SW: start 33, 1 bit, little-endian, init-value=0, base-type=uint8, implementation-data-type=DT_ICU_SLWF_SW, update-indication-bit-position=-1, to MVCU
      frame VCU_0xB6: id 0xB6, from MVCU, frame-length=16, can-addressing-mode=STANDARD, can-fd-frame-support=true, can-frame-tx-behavior=CAN-FD
        carries pdu VCU_0xB6: packing-byte-order=little-endian, start-position=0, update-indication-bit-position=-1
        pdu VCU_0xB6: length=16, transmission-mode-false-timing=cyclic-timing={time-offset=0.0, time-period=0.01}, transmission-mode-true-timing=cyclic-timing={time-offset=0.0, time-period=0.01}
          transmission-mode-conditions:
            {data-filter={data-filter-type=ALWAYS, max=255, min=0, offset=0}, i-signal-in-i-pdu=VCU_CRC_B6}
            {data-filter={data-filter-type=ALWAYS, max=1048575, min=0, offset=0}, i-signal-in-i-pdu=VCU_TVTest2}
            {data-filter={data-filter-type=ALWAYS, max=4095, min=0, offset=0}, i-signal-in-i-pdu=VCU_VPE_Test1}
            {data-filter={data-filter-type=ALWAYS, max=127, min=0, offset=0}, i-signal-in-i-pdu=VCU_VPE_Test2}
            {data-filter={data-filter-type=ALWAYS, max=32767, min=0, offset=0}, i-signal-in-i-pdu=VCU_TVTest1}
            {data-filter={data-filter-type=ALWAYS, max=15, min=0, offset=0}, i-signal-in-i-pdu=VCU_RollingCounter_B6}
            {data-filter={data-filter-type=NEW-IS-WITHIN, max=10000, min=0}, i-signal-in-i-pdu=VCU_MDrvRequestTorque_IDB6_CCAN}
            {data-filter={data-filter-type=NEW-IS-WITHIN, max=10000, min=0}, i-signal-in-i-pdu=VCU_MDriverRequireTorque}
            {data-filter={data-filter-type=NEW-IS-WITHIN, max=10000, min=0}, i-signal-in-i-pdu=VCU_SDrvRequestTorque_IDB6_CCAN}
            {data-filter={data-filter-type=NEW-IS-WITHIN, max=10000, min=0}, i-signal-in-i-pdu=VCU_SDriverRequireTorque}
            {data-filter={data-filter-type=ALWAYS, max=254, min=0, offset=0}, i-signal-in-i-pdu=VCU_ThrottlePosition_IDB6_CCAN}
            {data-filter={data-filter-type=ALWAYS, max=1, min=0, offset=0}, i-signal-in-i-pdu=VCU_AccPedalValid_IDB6_CCAN}
            {data-filter={data-filter-type=ALWAYS, max=1, min=0, offset=0}, i-signal-in-i-pdu=VCU_BrakeSysFault_IDB6_CCAN}
            {data-filter={data-filter-type=ALWAYS, max=1, min=0, offset=0}, i-signal-in-i-pdu=VCU_BrakeLightReq}
            {data-filter={data-filter-type=ALWAYS, max=1, min=0, offset=0}, i-signal-in-i-pdu=VCU_BrakePedalSts}
            {data-filter={data-filter-type=ALWAYS, max=1, min=0, offset=0}, i-signal-in-i-pdu=VCU_BrakePedalStsValid}
            {data-filter={data-filter-type=ALWAYS, max=3, min=0, offset=0}, i-signal-in-i-pdu=VCU_GearLevelPosSts_IDB6_CCAN}
            {data-filter={data-filter-type=ALWAYS, max=1, min=0, offset=0}, i-signal-in-i-pdu=VCU_GearLeverValid_IDB6_CCAN}
            {data-filter={data-filter-type=ALWAYS, max=1, min=0, offset=0}, i-signal-in-i-pdu=VCU_BrakeFirstSts}
            {data-filter={data-filter-type=ALWAYS, max=1, min=0, offset=0}, i-signal-in-i-pdu=VCU_DeliveryModeSts_IDB6_CCAN}
            {data-filter={data-filter-type=ALWAYS, max=10000, min=0, offset=0}, i-signal-in-i-pdu=VCU_MRDrvRequestTorque_IDB6_CCAN}
            {data-filter={data-filter-type=ALWAYS, max=10000, min=0, offset=0}, i-signal-in-i-pdu=VCU_MRDriverRequireTorque}
          signal VCU_CRC_B6: start 0, 8 bit, little-endian, init-value=0, base-type=uint8, implementation-data-type=DT_VCU_CRC_B6, update-indication-bit-position=-1
          signal VCU_TVTest2: start 172, 20 bit, little-endian, init-value=0, base-type=uint32, implementation-data-type=DT_VCU_TVTest2, update-indication-bit-position=-1
          signal VCU_VPE_Test1: start 160, 12 bit, little-endian, init-value=0, base-type=uint16, implementation-data-type=DT_VCU_VPE_Test1, update-indication-bit-position=-1
          signal VCU_VPE_Test2: start 121, 7 bit, little-endian, init-value=0, base-type=uint8, implementation-data-type=DT_VCU_VPE_Test2, update-indication-bit-position=-1
          signal VCU_TVTest1: start 106, 15 bit, little-endian, init-value=0, base-type=uint16, implementation-data-type=DT_VCU_TVTest1, update-indication-bit-position=-1
          signal VCU_RollingCounter_B6: start 8, 4 bit, little-endian, init-value=0, base-type=uint8, implementation-data-type=DT_VCU_RollingCounter_B6, update-indication-bit-position=-1
          signal VCU_MDrvRequestTorque_IDB6_CCAN: start 16, 16 bit, little-endian, init-value=0, base-type=uint16, implementation-data-type=DT_VCU_MDrvRequestTorque_IDB6_CCAN, update-indication-bit-position=-1
          signal VCU_MDriverRequireTorque: start 32, 16 bit, little-endian, init-value=0, base-type=uint16, implementation-data-type=DT_VCU_MDriverRequireTorque, update-indication-bit-position=-1
          signal VCU_SDrvRequestTorque_IDB6_CCAN: start 48, 16 bit, little-endian, init-value=0, base-type=uint16, implementation-data-type=DT_VCU_SDrvRequestTorque_IDB6_CCAN, update-indication-bit-position=-1
          signal VCU_SDriverRequireTorque: start 64, 16 bit, little-endian, init-value=0, base-type=uint16, implementation-data-type=DT_VCU_SDriverRequireTorque, update-indication-bit-position=-1
          signal VCU_ThrottlePosition_IDB6_CCAN: start 88, 8 bit, little-endian, init-value=0, base-type=uint8, implementation-data-type=DT_VCU_ThrottlePosition_IDB6_CCAN, update-indication-bit-position=-1
          signal VCU_AccPedalValid_IDB6_CCAN: start 96, 1 bit, little-endian, init-value=0, base-type=uint8, implementation-data-type=DT_VCU_AccPedalValid_IDB6_CCAN, update-indication-bit-position=-1
          signal VCU_BrakeSysFault_IDB6_CCAN: start 97, 1 bit, little-endian, init-value=0, base-type=uint8, implementation-data-type=DT_VCU_BrakeSysFault_IDB6_CCAN, update-indication-bit-position=-1
          signal VCU_BrakeLightReq: start 98, 1 bit, little-endian, init-value=0, base-type=uint8, implementation-data-type=DT_VCU_BrakeLightReq, update-indication-bit-position=-1
          signal VCU_BrakePedalSts: start 99, 1 bit, little-endian, init-value=0, base-type=uint8, implementation-data-type=DT_VCU_BrakePedalSts, update-indication-bit-position=-1
          signal VCU_BrakePedalStsValid: start 100, 1 bit, little-endian, init-value=0, base-type=uint8, implementation-data-type=DT_VCU_BrakePedalStsValid, update-indication-bit-position=-1
          signal VCU_GearLevelPosSts_IDB6_CCAN: start 101, 2 bit, little-endian, init-value=0, base-type=uint8, implementation-data-type=DT_VCU_GearLevelPosSts_IDB6_CCAN, update-indication-bit-position=-1
          signal VCU_GearLeverValid_IDB6_CCAN: start 103, 1 bit, little-endian, init-value=0, base-type=uint8, implementation-data-type=DT_VCU_GearLeverValid_IDB6_CCAN, update-indication-bit-position=-1
          signal VCU_BrakeFirstSts: start 104, 1 bit, little-endian, init-value=0, base-type=uint8, implementation-data-type=DT_VCU_BrakeFirstSts, update-indication-bit-position=-1
          signal VCU_DeliveryModeSts_IDB6_CCAN: start 105, 1 bit, little-endian, init-value=0, base-type=uint8, implementation-data-type=DT_VCU_DeliveryModeSts_IDB6_CCAN, update-indication-bit-position=-1
          signal VCU_MRDrvRequestTorque_IDB6_CCAN: start 128, 16 bit, little-endian, init-value=0, base-type=uint16, implementation-data-type=DT_VCU_MRDrvRequestTorque_IDB6_CCAN, update-indication-bit-position=-1
          signal VCU_MRDriverRequireTorque: start 144, 16 bit, little-endian, init-value=0, base-type=uint8, implementation-data-type=DT_VCU_MRDriverRequireTorque, update-indication-bit-position=-1
      frame VCU_0xB7: id 0xB7, from MVCU, frame-length=32, can-addressing-mode=STANDARD, can-fd-frame-support=true, can-frame-tx-behavior=CAN-FD
        carries pdu VCU_0xB7: packing-byte-order=little-endian, start-position=0, update-indication-bit-position=-1
        pdu VCU_0xB7: length=32
          signal VCU_CRC_B7: start 0, 8 bit, little-endian, init-value=0, base-type=uint8, implementation-data-type=DT_VCU_CRC_B7, update-indication-bit-position=-1
          signal VCU_KeepWorkModeFlag: start 21, 1 bit, little-endian, init-value=0, base-type=uint8, implementation-data-type=DT_VCU_KeepWorkModeFlag, update-indication-bit-position=-1
          signal VCU_MAI_Active: start 191, 1 bit, little-endian, init-value=0, base-type=uint8, implementation-data-type=DT_VCU_MAI_Active, update-indication-bit-position=-1
          signal VCU_MAI_Available: start 190, 1 bit, little-endian, init-value=0, base-type=uint8, implementation-data-type=DT_VCU_MAI_Available, update-indication-bit-position=-1
          signal VCU_GetCrashStsReq: start 184, 1 bit, little-endian, init-value=0, base-type=uint8, implementation-data-type=DT_VCU_GetCrashStsReq, update-indication-bit-position=-1
          signal VCU_ADASPosTorqueCap_VD: start 183, 1 bit, little-endian, init-value=0, base-type=uint8, implementation-data-type=DT_VCU_ADASPosTorqueCap_VD, update-indication-bit-position=-1
          signal VCU_ADASPosTorqueCap: start 169, 14 bit, little-endian, init-value=0, base-type=uint16, implementation-data-type=DT_VCU_ADASPosTorqueCap, update-indication-bit-position=-1
          signal VCU_RollingCounter_B7: start 8, 4 bit, little-endian, init-value=0, base-type=uint8, implementation-data-type=DT_VCU_RollingCounter_B7, update-indication-bit-position=-1
          signal VCU_Vehicle_Warning_IDB7_CCAN: start 16, 2 bit, little-endian, init-value=0, base-type=uint8, implementation-data-type=DT_VCU_Vehicle_Warning_IDB7_CCAN, update-indication-bit-position=-1
          signal VCU_VehicleSts_IDB7_CCAN: start 18, 1 bit, little-endian, init-value=0, base-type=uint8, implementation-data-type=DT_VCU_VehicleSts_IDB7_CCAN, update-indication-bit-position=-1
          signal VCU_PowerReduceReq: start 19, 2 bit, little-endian, init-value=0, base-type=uint8, implementation-data-type=DT_VCU_PowerReduceReq, update-indication-bit-position=-1
          signal VCU_ParkingReqToEPB_VD: start 24, 2 bit, little-endian, init-value=0, base-type=uint8, implementation-data-type=DT_VCU_ParkingReqToEPB_VD, update-indication-bit-position=-1
          signal VCU_ParkingReqToEPB: start 26, 2 bit, little-endian, init-value=0, base-type=uint8, implementation-data-type=DT_VCU_ParkingReqToEPB, update-indication-bit-position=-1
          signal VCU_ACCAvailable: start 28, 2 bit, little-endian, init-value=0, base-type=uint8, implementation-data-type=DT_VCU_ACCAvailable, update-indication-bit-position=-1
          signal VCU_ACCActiveSts: start 30, 1 bit, little-endian, init-value=0, base-type=uint8, implementation-data-type=DT_VCU_ACCActiveSts, update-indication-bit-position=-1
          signal VCU_Active_APS: start 31, 1 bit, little-endian, init-value=0, base-type=uint8, implementation-data-type=DT_VCU_Active_APS, update-indication-bit-position=-1
          signal VCU_Available_APS: start 32, 1 bit, little-endian, init-value=0, base-type=uint8, implementation-data-type=DT_VCU_Available_APS, update-indication-bit-position=-1
          signal VCU_ESCActive: start 33, 1 bit, little-endian, init-value=0, base-type=uint8, implementation-data-type=DT_VCU_ESCActive, update-indication-bit-position=-1
          signal VCU_ESCTorqReqAvailability_Rear: start 34, 1 bit, little-endian, init-value=0, base-type=uint8, implementation-data-type=DT_VCU_ESCTorqReqAvailability_Rear, update-indication-bit-position=-1
          signal VCU_AutoHold_ibit: start 35, 1 bit, little-endian, init-value=0, base-type=uint8, implementation-data-type=DT_VCU_AutoHold_ibit, update-indication-bit-position=-1
          signal VCU_VehicleSpeedVD: start 36, 2 bit, little-endian, init-value=0, base-type=uint8, implementation-data-type=DT_VCU_VehicleSpeedVD, update-indication-bit-position=-1
          signal VCU_CCSStatus: start 38, 2 bit, little-endian, init-value=0, base-type=uint8, implementation-data-type=DT_VCU_CCSStatus, update-indication-bit-position=-1
          signal VCU_AutoDriveRequest: start 40, 2 bit, little-endian, init-value=0, base-type=uint8, implementation-data-type=DT_VCU_AutoDriveRequest, update-indication-bit-position=-1
          signal VCU_CCSAllow: start 42, 1 bit, little-endian, init-value=0, base-type=uint8, implementation-data-type=DT_VCU_CCSAllow, update-indication-bit-position=-1
          signal VCU_VlcHoldSts: start 43, 1 bit, little-endian, init-value=0, base-type=uint8, implementation-data-type=DT_VCU_VlcHoldSts, update-indication-bit-position=-1
          signal VCU_HoldReqSts: start 44, 2 bit, little-endian, init-value=0, base-type=uint8, implementation-data-type=DT_VCU_HoldReqSts, update-indication-bit-position=-1
          signal VCU_DriverAssistProhibitSts_IDB7_CCAN: start 46, 1 bit, little-endian, init-value=0, base-type=uint8, implementation-data-type=DT_VCU_DriverAssistProhibitSts_IDB7_CCAN, update-indication-bit-position=-1
          signal VCU_SpeedLimitedSts: start 47, 1 bit, little-endian, init-value=0, base-type=uint8, implementation-data-type=DT_VCU_SpeedLimitedSts, update-indication-bit-position=-1
          signal VCU_SpeedLimitedValue: start 48, 8 bit, little-endian, init-value=0, base-type=uint8, implementation-data-type=DT_VCU_SpeedLimitedValue, update-indication-bit-position=-1
          signal VCU_TheoAccePedalPercent: start 56, 8 bit, little-endian, init-value=0, base-type=uint8, implementation-data-type=DT_VCU_TheoAccePedalPercent, update-indication-bit-position=-1
          signal VCU_RecuBrakeTorqueCap: start 64, 15 bit, little-endian, init-value=0, base-type=uint16, implementation-data-type=DT_VCU_RecuBrakeTorqueCap, update-indication-bit-position=-1
          signal VCU_HoldReqStsValid: start 79, 1 bit, little-endian, init-value=0, base-type=uint8, implementation-data-type=DT_VCU_HoldReqStsValid, update-indication-bit-position=-1
          signal VCU_RecuBrakeTorqueAct: start 80, 15 bit, little-endian, init-value=0, base-type=uint16, implementation-data-type=DT_VCU_RecuBrakeTorqueAct, update-indication-bit-position=-1
          signal VCU_TheoAccePedalValid: start 96, 1 bit, little-endian, init-value=0, base-type=uint8, implementation-data-type=DT_VCU_TheoAccePedalValid, update-indication-bit-position=-1
          signal VCU_HydraTorqTgt: start 97, 15 bit, little-endian, init-value=0, base-type=uint16, implementation-data-type=DT_VCU_HydraTorqTgt, update-indication-bit-position=-1
          signal VCU_RecuBrakeTorqueActDrag: start 112, 15 bit, little-endian, init-value=0, base-type=uint16, implementation-data-type=DT_VCU_RecuBrakeTorqueActDrag, update-indication-bit-position=-1
          signal VCU_ESCTorqReqAvailability_Frnt: start 127, 1 bit, little-endian, init-value=0, base-type=uint8, implementation-data-type=DT_VCU_ESCTorqReqAvailability_Frnt, update-indication-bit-position=-1
          signal VCU_RecuBrakeTorqueCap_Q: start 128, 2 bit, little-endian, init-value=0, base-type=uint8, implementation-data-type=DT_VCU_RecuBrakeTorqueCap_Q, update-indication-bit-position=-1
          signal VCU_RecuBrakeTorqueAct_Q: start 130, 2 bit, little-endian, init-value=0, base-type=uint8, implementation-data-type=DT_VCU_RecuBrakeTorqueAct_Q, update-indication-bit-position=-1
          signal VCU_HydraTorqTgt_Q: start 132, 2 bit, little-endian, init-value=0, base-type=uint8, implementation-data-type=DT_VCU_HydraTorqTgt_Q, update-indication-bit-position=-1
          signal VCU_RecuBrakeTorqueActDrag_Q: start 134, 2 bit, little-endian, init-value=0, base-type=uint8, implementation-data-type=DT_VCU_RecuBrakeTorqueActDrag_Q, update-indication-bit-position=-1
          signal VCU_RecuBrakeTorqueTarget_Drag: start 136, 15 bit, little-endian, init-value=0, base-type=uint16, implementation-data-type=DT_VCU_RecuBrakeTorqueTarget_Drag, update-indication-bit-position=-1
          signal VCU_PreventVehSlipSts: start 151, 1 bit, little-endian, init-value=0, base-type=uint8, implementation-data-type=DT_VCU_PreventVehSlipSts, update-indication-bit-position=-1
          signal VCU_RecuBrakeTorqueTarget_Drag_Q: start 152, 2 bit, little-endian, init-value=0, base-type=uint8, implementation-data-type=DT_VCU_RecuBrakeTorqueTarget_Drag_Q, update-indication-bit-position=-1
          signal VCU_AllMotWhlTrqFB: start 154, 14 bit, little-endian, init-value=0, base-type=uint16, implementation-data-type=DT_VCU_AllMotWhlTrqFB, update-indication-bit-position=-1
          signal VCU_AllMotWhlTrqFB_VD: start 168, 1 bit, little-endian, init-value=0, base-type=uint8, implementation-data-type=DT_VCU_AllMotWhlTrqFB_VD, update-indication-bit-position=-1
          signal VCU_LSFC_Allow: start 186, 1 bit, little-endian, init-value=0, base-type=uint8, implementation-data-type=DT_VCU_LSFC_Allow, update-indication-bit-position=-1
          signal VCU_LSFC_Active: start 187, 1 bit, little-endian, init-value=0, base-type=uint8, implementation-data-type=DT_VCU_LSFC_Active, update-indication-bit-position=-1
          signal VCU_MGCUWorkMode_C: start 188, 2 bit, little-endian, init-value=0, base-type=uint8, implementation-data-type=DT_VCU_MGCUWorkMode_C, update-indication-bit-position=-1
          signal VCU_AllRoadSts: start 221, 3 bit, little-endian, init-value=0, base-type=uint8, implementation-data-type=DT_VCU_AllRoadSts, update-indication-bit-position=-1
          signal VCU_CmpUTurnAllow: start 224, 1 bit, little-endian, init-value=0, base-type=uint8, implementation-data-type=DT_VCU_CmpUTurnAllow, update-indication-bit-position=-1
          signal VCU_CmpUTurnSts: start 225, 2 bit, little-endian, init-value=0, base-type=uint8, implementation-data-type=DT_VCU_CmpUTurnSts, update-indication-bit-position=-1
          signal VCU_AllowCmpUTurnStartFlag: start 227, 1 bit, little-endian, init-value=0, base-type=uint8, implementation-data-type=DT_VCU_AllowCmpUTurnStartFlag, update-indication-bit-position=-1
          signal VCU_CmpUTurnLockWhl: start 228, 3 bit, little-endian, init-value=0, base-type=uint8, implementation-data-type=DT_VCU_CmpUTurnLockWhl, update-indication-bit-position=-1
          signal VCU_CmpUTurnActAngle: start 231, 9 bit, little-endian, init-value=0, base-type=uint16, implementation-data-type=DT_VCU_CmpUTurnActAngle, update-indication-bit-position=-1
          signal VCU_CmpUTurnActSpinSpd: start 240, 4 bit, little-endian, init-value=0, base-type=uint8, implementation-data-type=DT_VCU_CmpUTurnActSpinSpd, update-indication-bit-position=-1
          signal VCU_CmpUTurnFltHMI: start 244, 4 bit, little-endian, init-value=0, base-type=uint8, implementation-data-type=DT_VCU_CmpUTurnFltHMI, update-indication-bit-position=-1
          signal VCU_EscapeModeSts: start 207, 1 bit, little-endian, init-value=0, base-type=uint8, implementation-data-type=DT_VCU_EscapeModeSts, update-indication-bit-position=-1
          signal VCU_MCUSWorkFailMsg: start 208, 3 bit, little-endian, init-value=0, base-type=uint8, implementation-data-type=DT_VCU_MCUSWorkFailMsg, update-indication-bit-position=-1
          signal VCU_EscapeWorkFailMsg: start 211, 3 bit, little-endian, init-value=0, base-type=uint8, implementation-data-type=DT_VCU_EscapeWorkFailMsg, update-indication-bit-position=-1
          signal VCU_REClutchFltMsg: start 214, 2 bit, little-endian, init-value=0, base-type=uint8, implementation-data-type=DT_VCU_REClutchFltMsg, update-indication-bit-position=-1
          signal VCU_BoostMode_Fail_C: start 216, 3 bit, little-endian, init-value=0, base-type=uint8, update-indication-bit-position=-1
          signal VCU_BoostModeSts_C: start 219, 2 bit, little-endian, init-value=0, base-type=uint8, update-indication-bit-position=-1
      frame VCU_0xE6: id 0xE6, from MVCU, frame-length=64, can-addressing-mode=STANDARD, can-fd-frame-support=true, can-frame-tx-behavior=CAN-FD
        carries pdu VCU_0xE6: packing-byte-order=little-endian, start-position=0, update-indication-bit-position=-1
        pdu VCU_0xE6: length=64
          signal DbgSignal1_FA: start 0, 16 bit, little-endian, init-value=0, base-type=uint16, update-indication-bit-position=-1
          signal DbgSignal2_FA: start 16, 16 bit, little-endian, init-value=0, base-type=uint16, update-indication-bit-position=-1
          signal DbgSignal3_FA: start 32, 16 bit, little-endian, init-value=0, base-type=uint16, update-indication-bit-position=-1
          signal DbgSignal4_FA: start 48, 16 bit, little-endian, init-value=0, base-type=uint16, update-indication-bit-position=-1
          signal DbgSignal5_FA: start 64, 16 bit, little-endian, init-value=0, base-type=uint16, update-indication-bit-position=-1
          signal DbgSignal6_FA: start 80, 16 bit, little-endian, init-value=0, base-type=uint16, update-indication-bit-position=-1
          signal DbgSignal7_FA: start 96, 16 bit, little-endian, init-value=0, base-type=uint16, update-indication-bit-position=-1
          signal DbgSignal8_FA: start 112, 16 bit, little-endian, init-value=0, base-type=uint16, update-indication-bit-position=-1
          signal DbgSignal9_FA: start 128, 16 bit, little-endian, init-value=0, base-type=uint16, update-indication-bit-position=-1
          signal DbgSignal10_FA: start 144, 16 bit, little-endian, init-value=0, base-type=uint16, update-indication-bit-position=-1
          signal DbgSignal11_FA: start 160, 16 bit, little-endian, init-value=0, base-type=uint16, update-indication-bit-position=-1
          signal DbgSignal12_FA: start 176, 16 bit, little-endian, init-value=0, base-type=uint16, update-indication-bit-position=-1
          signal DbgSignal1_RA: start 192, 16 bit, little-endian, init-value=0, base-type=uint16, update-indication-bit-position=-1
          signal DbgSignal2_RA: start 208, 16 bit, little-endian, init-value=0, base-type=uint16, update-indication-bit-position=-1
          signal DbgSignal3_RA: start 224, 16 bit, little-endian, init-value=0, base-type=uint16, update-indication-bit-position=-1
          signal DbgSignal4_RA: start 240, 16 bit, little-endian, init-value=0, base-type=uint16, update-indication-bit-position=-1
          signal DbgSignal5_RA: start 256, 16 bit, little-endian, init-value=0, base-type=uint16, update-indication-bit-position=-1
          signal DbgSignal6_RA: start 272, 16 bit, little-endian, init-value=0, base-type=uint16, update-indication-bit-position=-1
          signal DbgSignal7_RA: start 288, 16 bit, little-endian, init-value=0, base-type=uint16, update-indication-bit-position=-1
          signal DbgSignal8_RA: start 304, 16 bit, little-endian, init-value=0, base-type=uint16, update-indication-bit-position=-1
          signal DbgSignal9_RA: start 320, 16 bit, little-endian, init-value=0, base-type=uint16, update-indication-bit-position=-1
          signal DbgSignal10_RA: start 336, 16 bit, little-endian, init-value=0, base-type=uint16, update-indication-bit-position=-1
          signal DbgSignal11_RA: start 352, 16 bit, little-endian, init-value=0, base-type=uint16, update-indication-bit-position=-1
          signal DbgSignal12_RA: start 368, 16 bit, little-endian, init-value=0, base-type=uint16, update-indication-bit-position=-1
      frame IBC_0x136: id 0x136, to MVCU, frame-length=32, can-addressing-mode=STANDARD, can-fd-frame-support=true, can-frame-rx-behavior=CAN-FD
        carries pdu IBC_0x136: packing-byte-order=little-endian, start-position=0, update-indication-bit-position=-1
        pdu IBC_0x136: length=32, transmission-mode-false-timing=cyclic-timing={time-offset=0.0, time-period=0.01}, transmission-mode-true-timing=cyclic-timing={time-offset=0.0, time-period=0.01}
          transmission-mode-conditions:
            {data-filter={data-filter-type=ALWAYS, max=255, min=0, offset=0}, i-signal-in-i-pdu=IBC_CRC_136}
            {data-filter={data-filter-type=ALWAYS, max=15, min=0, offset=0}, i-signal-in-i-pdu=IBC_RollingCounter_136}
            {data-filter={data-filter-type=NEW-IS-WITHIN, max=3, min=0, offset=0}, i-signal-in-i-pdu=IBC_ModeMinEDrvTar_FA}
            {data-filter={data-filter-type=NEW-IS-WITHIN, max=3, min=0, offset=0}, i-signal-in-i-pdu=IBC_ModeMinEDrvTar_RA}
            {data-filter={data-filter-type=NEW-IS-WITHIN, max=3, min=0, offset=0}, i-signal-in-i-pdu=IBC_ModeMaxEDrvTar_FA}
            {data-filter={data-filter-type=NEW-IS-WITHIN, max=3, min=0, offset=0}, i-signal-in-i-pdu=IBC_ModeMaxEDrvTar_RA}
            {data-filter={data-filter-type=NEW-IS-WITHIN, max=1, min=0, offset=0}, i-signal-in-i-pdu=IBC_torque_distribution_RA_Vaild}
            {data-filter={data-filter-type=NEW-IS-WITHIN, max=255, min=0, offset=0}, i-signal-in-i-pdu=IBC_torque_distribution_RA}
            {data-filter={data-filter-type=NEW-IS-WITHIN, max=65535, min=0, offset=0}, i-signal-in-i-pdu=IBC_mTar_FA}
            {data-filter={data-filter-type=NEW-IS-WITHIN, max=65535, min=0, offset=0}, i-signal-in-i-pdu=IBC_mTar_RA}
            {data-filter={data-filter-type=NEW-IS-WITHIN, max=255, min=0, offset=0}, i-signal-in-i-pdu=IBC_iLDC_SWInfo}
            {data-filter={data-filter-type=NEW-IS-WITHIN, max=255, min=0, offset=0}, i-signal-in-i-pdu=IBC_Variant_Signal}
            {data-filter={data-filter-type=NEW-IS-WITHIN, max=65472, min=0}, i-signal-in-i-pdu=IBC_nTarMax_FA}
            {data-filter={data-filter-type=NEW-IS-WITHIN, max=65472, min=0}, i-signal-in-i-pdu=IBC_nTarMax_RA}
            {data-filter={data-filter-type=NEW-IS-WITHIN, max=65472, min=0}, i-signal-in-i-pdu=IBC_nTarMin_FA}
            {data-filter={data-filter-type=NEW-IS-WITHIN, max=65472, min=0}, i-signal-in-i-pdu=IBC_nTarMin_RA}
          signal IBC_CRC_136: start 0, 8 bit, little-endian, init-value=0, base-type=uint8, update-indication-bit-position=-1, to MVCU
          signal IBC_RollingCounter_136: start 8, 4 bit, little-endian, init-value=0, base-type=uint8, update-indication-bit-position=-1, to MVCU
          signal IBC_ModeMinEDrvTar_FA: start 100, 2 bit, little-endian, init-value=0, base-type=uint8, update-indication-bit-position=-1, to MVCU
          signal IBC_ModeMinEDrvTar_RA: start 102, 2 bit, little-endian, init-value=0, base-type=uint8, update-indication-bit-position=-1, to MVCU
          signal IBC_ModeMaxEDrvTar_FA: start 104, 2 bit, little-endian, init-value=0, base-type=uint8, update-indication-bit-position=-1, to MVCU
          signal IBC_ModeMaxEDrvTar_RA: start 106, 2 bit, little-endian, init-value=0, base-type=uint8, update-indication-bit-position=-1, to MVCU
          signal IBC_torque_distribution_RA_Vaild: start 119, 1 bit, little-endian, init-value=0, base-type=uint8, update-indication-bit-position=-1, to MVCU
          signal IBC_torque_distribution_RA: start 120, 8 bit, little-endian, init-value=0, base-type=uint8, update-indication-bit-position=-1, to MVCU
          signal IBC_mTar_FA: start 128, 16 bit, little-endian, init-value=0, base-type=uint16, update-indication-bit-position=-1, to MVCU
          signal IBC_mTar_RA: start 144, 16 bit, little-endian, init-value=0, base-type=uint16, update-indication-bit-position=-1, to MVCU
          signal IBC_iLDC_SWInfo: start 160, 8 bit, little-endian, init-value=0, base-type=uint8, update-indication-bit-position=-1, to MVCU
          signal IBC_Variant_Signal: start 168, 8 bit, little-endian, init-value=0, base-type=uint16, update-indication-bit-position=-1, to MVCU
          signal IBC_nTarMax_FA: start 192, 16 bit, little-endian, init-value=0, base-type=uint16, update-indication-bit-position=-1, to MVCU
          signal IBC_nTarMax_RA: start 208, 16 bit, little-endian, init-value=0, base-type=uint16, update-indication-bit-position=-1, to MVCU
          signal IBC_nTarMin_FA: start 224, 16 bit, little-endian, init-value=0, base-type=uint16, update-indication-bit-position=-1, to MVCU
          signal IBC_nTarMin_RA: start 240, 16 bit, little-endian, init-value=0, base-type=uint16, update-indication-bit-position=-1, to MVCU
      frame MCUM_0x135: id 0x135, from MVCU, frame-length=16, can-addressing-mode=STANDARD, can-fd-frame-support=true, can-frame-tx-behavior=CAN-FD
        carries pdu MCUM_0x135: packing-byte-order=little-endian, start-position=0, update-indication-bit-position=-1
        pdu MCUM_0x135: length=16, transmission-mode-false-timing=cyclic-timing={time-offset=0.0, time-period=0.01}, transmission-mode-true-timing=cyclic-timing={time-offset=0.0, time-period=0.01}
          transmission-mode-conditions:
            {data-filter={data-filter-type=ALWAYS, max=255, min=0, offset=0}, i-signal-in-i-pdu=MCUM_CRC_135}
            {data-filter={data-filter-type=ALWAYS, max=15, min=0, offset=0}, i-signal-in-i-pdu=MCUM_RollingCounter_135}
            {data-filter={data-filter-type=NEW-IS-WITHIN, max=65534, min=0, offset=0}, i-signal-in-i-pdu=MCUM_LDC_SWInfo}
            {data-filter={data-filter-type=NEW-IS-WITHIN, max=60000, min=0}, i-signal-in-i-pdu=MCUM_LDC_MTarOut_FA}
            {data-filter={data-filter-type=NEW-IS-WITHIN, max=60000, min=0}, i-signal-in-i-pdu=MCUM_LDC_MTarOut_RA}
            {data-filter={data-filter-type=ALWAYS, max=1, min=0, offset=0}, i-signal-in-i-pdu=MCUM_LDC_Available_FA}
            {data-filter={data-filter-type=ALWAYS, max=7, min=0, offset=0}, i-signal-in-i-pdu=MCUM_LDC_OperationMode_FA}
            {data-filter={data-filter-type=ALWAYS, max=1, min=0, offset=0}, i-signal-in-i-pdu=MCUM_LDC_Available_RA}
            {data-filter={data-filter-type=ALWAYS, max=7, min=0, offset=0}, i-signal-in-i-pdu=MCUM_LDC_OperationMode_RA}
            {data-filter={data-filter-type=ALWAYS, max=255, min=0, offset=0}, i-signal-in-i-pdu=MCUM_RTE_Exchange_Signal_Status}
            {data-filter={data-filter-type=ALWAYS, max=65535, min=0, offset=0}, i-signal-in-i-pdu=MCUM_MTarIn_FA}
            {data-filter={data-filter-type=ALWAYS, max=65535, min=0, offset=0}, i-signal-in-i-pdu=MCUM_MTarIn_RA}
            {data-filter={data-filter-type=ALWAYS, max=1, min=0, offset=0}, i-signal-in-i-pdu=MCUM_InputQF_FA}
            {data-filter={data-filter-type=ALWAYS, max=1, min=0, offset=0}, i-signal-in-i-pdu=MCUM_InputQF_RA}
          signal MCUM_CRC_135: start 0, 8 bit, little-endian, init-value=0, base-type=uint8, update-indication-bit-position=-1
          signal MCUM_RollingCounter_135: start 8, 4 bit, little-endian, init-value=0, base-type=uint8, update-indication-bit-position=-1
          signal MCUM_LDC_SWInfo: start 16, 16 bit, little-endian, init-value=0, base-type=uint16, update-indication-bit-position=-1
          signal MCUM_LDC_MTarOut_FA: start 32, 16 bit, little-endian, init-value=0, base-type=uint16, update-indication-bit-position=-1
          signal MCUM_LDC_MTarOut_RA: start 48, 16 bit, little-endian, init-value=0, base-type=uint16, update-indication-bit-position=-1
          signal MCUM_LDC_Available_FA: start 64, 1 bit, little-endian, init-value=0, base-type=uint8, update-indication-bit-position=-1
          signal MCUM_LDC_OperationMode_FA: start 66, 3 bit, little-endian, init-value=0, base-type=uint8, update-indication-bit-position=-1
          signal MCUM_LDC_Available_RA: start 65, 1 bit, little-endian, init-value=0, base-type=uint8, update-indication-bit-position=-1
          signal MCUM_LDC_OperationMode_RA: start 69, 3 bit, little-endian, init-value=0, base-type=uint8, update-indication-bit-position=-1
          signal MCUM_RTE_Exchange_Signal_Status: start 72, 8 bit, little-endian, init-value=0, base-type=uint8, update-indication-bit-position=-1
          signal MCUM_MTarIn_FA: start 80, 16 bit, little-endian, init-value=0, base-type=uint16, update-indication-bit-position=-1
          signal MCUM_MTarIn_RA: start 96, 16 bit, little-endian, init-value=0, base-type=uint16, update-indication-bit-position=-1
          signal MCUM_InputQF_FA: start 112, 1 bit, little-endian, init-value=0, base-type=uint8, update-indication-bit-position=-1
          signal MCUM_InputQF_RA: start 113, 1 bit, little-endian, init-value=0, base-type=uint8, update-indication-bit-position=-1
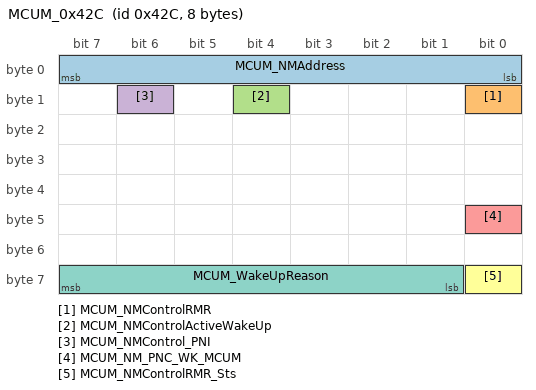
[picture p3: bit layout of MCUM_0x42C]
      frame MCUM_0x42C: id 0x42C, from MVCU, frame-length=8, can-addressing-mode=STANDARD, can-frame-tx-behavior=CAN-FD
        carries pdu MCUM_0x42C: packing-byte-order=little-endian, start-position=0, update-indication-bit-position=-1
        nm pdu MCUM_0x42C: length=8, nm-data-information=false, nm-vote-information=false
          signal MCUM_NMAddress: start 0, 8 bit, little-endian, init-value=0, base-type=uint8, update-indication-bit-position=-1
          signal MCUM_NMControlRMR: start 8, 1 bit, little-endian, init-value=0, base-type=uint8, update-indication-bit-position=-1
          signal MCUM_NMControlActiveWakeUp: start 12, 1 bit, little-endian, init-value=0, base-type=uint8, update-indication-bit-position=-1
          signal MCUM_NMControl_PNI: start 14, 1 bit, little-endian, init-value=0, base-type=uint8, update-indication-bit-position=-1
          signal MCUM_NM_PNC_WK_MCUM: start 40, 1 bit, little-endian, init-value=0, base-type=uint8, update-indication-bit-position=-1
          signal MCUM_NMControlRMR_Sts: start 56, 1 bit, little-endian, init-value=0, base-type=uint8, implementation-data-type=DT_MCUM_NMControlRMR_Sts, update-indication-bit-position=-1
          signal MCUM_WakeUpReason: start 57, 7 bit, little-endian, init-value=0, base-type=uint8, implementation-data-type=DT_MCUM_WakeUpReason, update-indication-bit-position=-1
      frame LMC_0x133: id 0x133, to MVCU, frame-length=32, can-addressing-mode=STANDARD, can-fd-frame-support=true, can-frame-rx-behavior=CAN-FD
        carries pdu LMC_0x133: packing-byte-order=little-endian, start-position=0, update-indication-bit-position=-1
        pdu LMC_0x133: length=32, transmission-mode-false-timing=cyclic-timing={time-offset=0.0, time-period=0.01}, transmission-mode-true-timing=cyclic-timing={time-offset=0.0, time-period=0.01}
          transmission-mode-conditions:
            {data-filter={data-filter-type=ALWAYS, max=255, min=0, offset=0}, i-signal-in-i-pdu=LMC_CRC_133}
            {data-filter={data-filter-type=ALWAYS, max=32767, min=0, offset=0}, i-signal-in-i-pdu=LMC_DrvReqTorque}
            {data-filter={data-filter-type=ALWAYS, max=15, min=0, offset=0}, i-signal-in-i-pdu=LMC_RollingCounter_133}
          signal LMC_CRC_133: start 0, 8 bit, little-endian, init-value=0, base-type=uint8, compu {raw=phys for phys 0..255; unit Pkg_Units/NOUNIT}, update-indication-bit-position=-1, to MVCU  # Ð£ÑéÎ»"
          signal LMC_DrvReqTorque: start 40, 15 bit, little-endian, init-value=0, base-type=uint16, compu {raw=phys for phys 0..32767; unit Pkg_Units/NOUNIT}, update-indication-bit-position=-1, to MVCU  # Ð£ÑéÎ»"
          signal LMC_RollingCounter_133: start 8, 4 bit, little-endian, init-value=0, base-type=uint8, compu {raw=phys for phys 0..15; unit Pkg_Units/NOUNIT}, update-indication-bit-position=-1, to MVCU  # Ð£ÑéÎ»"
      frame LMCSSU_0x25A: id 0x25A, to MVCU, frame-length=32, can-addressing-mode=STANDARD, can-fd-frame-support=true, can-frame-rx-behavior=CAN-FD
        carries pdu LMCSSU_0x25A: packing-byte-order=little-endian, start-position=0, update-indication-bit-position=-1
        pdu LMCSSU_0x25A: length=32, transmission-mode-false-timing=cyclic-timing={time-offset=0.0, time-period=0.1}, transmission-mode-true-timing=cyclic-timing={time-offset=0.0, time-period=0.1}
          transmission-mode-conditions:
            {data-filter={data-filter-type=ALWAYS, max=255, min=0, offset=0}, i-signal-in-i-pdu=LMC_CRC_25A}
            {data-filter={data-filter-type=ALWAYS, max=15, min=0, offset=0}, i-signal-in-i-pdu=LMC_ECAS_DriveModeFb}
            {data-filter={data-filter-type=ALWAYS, max=7, min=0, offset=0}, i-signal-in-i-pdu=LMC_CDC_DriveModeFb}
            {data-filter={data-filter-type=ALWAYS, max=15, min=0, offset=0}, i-signal-in-i-pdu=LMC_RollingCounter_25A}
          signal LMC_CRC_25A: start 0, 8 bit, little-endian, init-value=0, base-type=uint8, compu {raw=phys for phys 0..255}, update-indication-bit-position=-1, to MVCU  # Ð£ÑéÎ»"
          signal LMC_ECAS_DriveModeFb: start 44, 4 bit, little-endian, init-value=0, base-type=uint8, compu {raw=phys for phys 0..15}, update-indication-bit-position=-1, to MVCU  # Ð£ÑéÎ»"
          signal LMC_CDC_DriveModeFb: start 40, 3 bit, little-endian, init-value=0, base-type=uint8, compu {raw=phys for phys 0..7}, update-indication-bit-position=-1, to MVCU  # Ð£ÑéÎ»"
          signal LMC_RollingCounter_25A: start 8, 4 bit, little-endian, init-value=0, base-type=uint8, compu {raw=phys for phys 0..15}, update-indication-bit-position=-1, to MVCU  # Ð£ÑéÎ»"
      frame HPCBCM_0x4A: id 0x4A, to MVCU, frame-length=1, can-addressing-mode=STANDARD, can-fd-frame-support=true, can-frame-rx-behavior=CAN-FD
        carries pdu HPCBCM_0x4A: packing-byte-order=little-endian, start-position=0, update-indication-bit-position=-1
        pdu HPCBCM_0x4A: length=1, transmission-mode-false-timing=cyclic-timing={time-offset=0.0, time-period=0.01}, transmission-mode-true-timing=cyclic-timing={time-offset=0.0, time-period=0.01}
          transmission-mode-conditions:
            {data-filter={data-filter-type=ALWAYS, max=255, min=0, offset=0}, i-signal-in-i-pdu=BCM_CRC_4A}
            {data-filter={data-filter-type=ALWAYS, max=1, min=0, offset=0}, i-signal-in-i-pdu=BCM_IBCLimphomeSts}
            {data-filter={data-filter-type=ALWAYS, max=1, min=0, offset=0}, i-signal-in-i-pdu=BCM_EOLAutomaticActiveSts_C}
            {data-filter={data-filter-type=ALWAYS, max=65535, min=0, offset=0}, i-signal-in-i-pdu=BCM_TorqueLimte}
            {data-filter={data-filter-type=ALWAYS, max=15, min=0, offset=0}, i-signal-in-i-pdu=BCM_RollingCounter_4A}
          signal BCM_CRC_4A: start 0, 8 bit, little-endian, init-value=0, compu {raw=phys for phys 0..255; unit Pkg_Units/NOUNIT}, update-indication-bit-position=-1, to MVCU  # Ð£ÑéÎ»"
          signal BCM_IBCLimphomeSts: start 33, 1 bit, little-endian, init-value=0, compu {raw=phys for phys 0..1; unit Pkg_Units/NOUNIT}, update-indication-bit-position=-1, to MVCU  # Ð£ÑéÎ»"
          signal BCM_EOLAutomaticActiveSts_C: start 32, 1 bit, little-endian, init-value=0, compu {raw=phys for phys 0..1; unit Pkg_Units/NOUNIT}, update-indication-bit-position=-1, to MVCU  # Ð£ÑéÎ»"
          signal BCM_TorqueLimte: start 16, 16 bit, little-endian, init-value=0, compu {raw=phys for phys 0..65535; unit Pkg_Units/NOUNIT}, update-indication-bit-position=-1, to MVCU  # Ð£ÑéÎ»"
          signal BCM_RollingCounter_4A: start 8, 4 bit, little-endian, init-value=0, compu {raw=phys for phys 0..15; unit Pkg_Units/NOUNIT}, update-indication-bit-position=-1, to MVCU  # Ð£ÑéÎ»"
package /DBC_SysDesc_C_CANFD/Pkg_Signal
  system signal IBC_maxmium_front_axle_targert_speed
